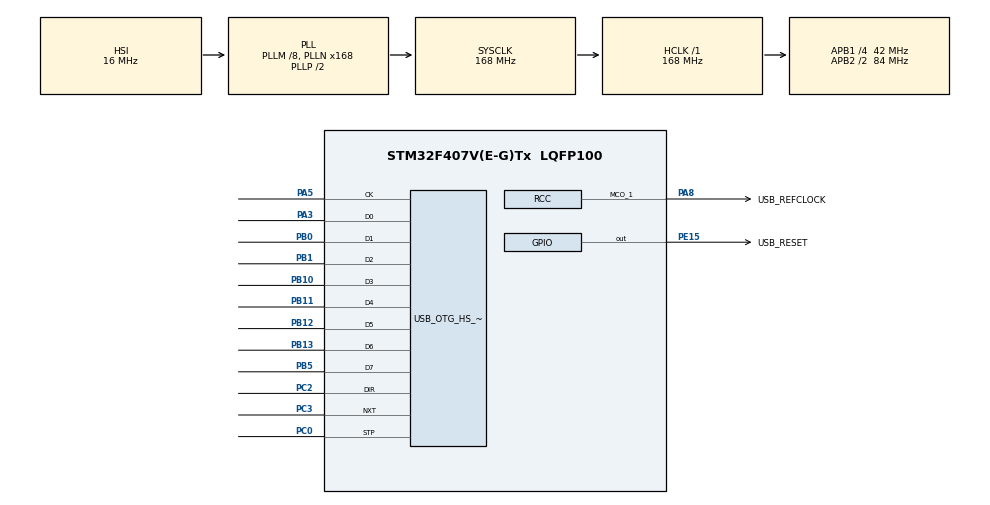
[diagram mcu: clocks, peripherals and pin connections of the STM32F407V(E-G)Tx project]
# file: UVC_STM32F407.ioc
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AL94.I-CUBE-USBD-COMPOSITE.1.0.3.CompositeCcUSBJjCOMPOSITEJjCDCIiACM=true
AL94.I-CUBE-USBD-COMPOSITE.1.0.3.CompositeCcUSBJjCOMPOSITEJjCOMPOSITE=true
AL94.I-CUBE-USBD-COMPOSITE.1.0.3.CompositeCcUSBJjCOMPOSITEJjCore=true
AL94.I-CUBE-USBD-COMPOSITE.1.0.3.CompositeCcUSBJjCOMPOSITEJjUVC=true
AL94.I-CUBE-USBD-COMPOSITE.1.0.3._USBD_USE_CDC_ACM=false
AL94.I-CUBE-USBD-COMPOSITE.1.0.3._USBD_USE_HS=true
AL94.I-CUBE-USBD-COMPOSITE.1.0.3._USBD_USE_UVC=true
Mcu.Family=STM32F4
Mcu.Name=STM32F407V(E-G)Tx
Mcu.Package=LQFP100
NVIC.OTG_HS_IRQn=true\:0\:0\:false\:false\:true\:true\:true\:true
NVIC.PriorityGroup=NVIC_PRIORITYGROUP_4
PA13.Mode=JTAG_5_pins
PA13.Signal=SYS_JTMS-SWDIO
PA14.Mode=JTAG_5_pins
PA14.Signal=SYS_JTCK-SWCLK
PA15.Mode=JTAG_5_pins
PA15.Signal=SYS_JTDI
PA3.Mode=Device_HS
PA3.Signal=USB_OTG_HS_ULPI_D0
PA5.Mode=Device_HS
PA5.Signal=USB_OTG_HS_ULPI_CK
PA8.GPIO_Label=USB_REFCLOCK
PA8.GPIO_Speed=GPIO_SPEED_FREQ_MEDIUM
PA8.Mode=Clock-out-1
PA8.Signal=RCC_MCO_1
PB0.Mode=Device_HS
PB0.Signal=USB_OTG_HS_ULPI_D1
PB1.Mode=Device_HS
PB1.Signal=USB_OTG_HS_ULPI_D2
PB10.Mode=Device_HS
PB10.Signal=USB_OTG_HS_ULPI_D3
PB11.Mode=Device_HS
PB11.Signal=USB_OTG_HS_ULPI_D4
PB12.Mode=Device_HS
PB12.Signal=USB_OTG_HS_ULPI_D5
PB13.Mode=Device_HS
PB13.Signal=USB_OTG_HS_ULPI_D6
PB3.Mode=JTAG_5_pins
PB3.Signal=SYS_JTDO-SWO
PB4.Mode=JTAG_5_pins
PB4.Signal=SYS_JTRST
PB5.Mode=Device_HS
PB5.Signal=USB_OTG_HS_ULPI_D7
PC0.Mode=Device_HS
PC0.Signal=USB_OTG_HS_ULPI_STP
PC2.Mode=Device_HS
PC2.Signal=USB_OTG_HS_ULPI_DIR
PC3.Mode=Device_HS
PC3.Signal=USB_OTG_HS_ULPI_NXT
PE1.Signal=DCMI_D3
PE15.GPIO_Label=USB_RESET
PE15.Signal=GPIO_Output
PH0-OSC_IN.Mode=HSE-External-Oscillator
PH0-OSC_IN.Signal=RCC_OSC_IN
PH1-OSC_OUT.Mode=HSE-External-Oscillator
PH1-OSC_OUT.Signal=RCC_OSC_OUT
ProjectManager.HeapSize=0x200
ProjectManager.StackSize=0x400
ProjectManager.TargetToolchain=STM32CubeIDE
RCC.48MHZClocksFreq_Value=84000000
RCC.AHBFreq_Value=168000000
RCC.APB1CLKDivider=RCC_HCLK_DIV4
RCC.APB1Freq_Value=42000000
RCC.APB1TimFreq_Value=84000000
RCC.APB2CLKDivider=RCC_HCLK_DIV2
RCC.APB2Freq_Value=84000000
RCC.APB2TimFreq_Value=168000000
RCC.CortexFreq_Value=168000000
RCC.HCLKFreq_Value=168000000
RCC.HSE_VALUE=24000000
RCC.HSI_VALUE=16000000
RCC.LSE_VALUE=32768
RCC.PLLM=8
RCC.PLLN=168
RCC.RCC_MCO1Source=RCC_MCO1SOURCE_HSE
RCC.RCC_MCO2Source=RCC_MCO2SOURCE_HSE
RCC.SYSCLKFreq_VALUE=168000000
RCC.SYSCLKSource=RCC_SYSCLKSOURCE_PLLCLK
RCC.VCOOutputFreq_Value=336000000
USB_OTG_HS.VirtualMode-Device_HS=Device_HS
USB_OTG_HS.dma_enable-Device_HS=DISABLE
USB_OTG_HS.low_power_enable-Device_HS=DISABLE
VP_AL94.I-CUBE-USBD-COMPOSITE_VS_USBJjComposite_1.0.0_1.0.3.Mode=USBJjComposite
board=custom

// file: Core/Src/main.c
/* USER CODE BEGIN Header */
/**
  ******************************************************************************
  * @file           : main.c
  * @brief          : Main program body
  ******************************************************************************
  * @attention
  *
  * Copyright (c) 2024 STMicroelectronics.
  * All rights reserved.
  *
  * This software is licensed under terms that can be found in the LICENSE file
  * in the root directory of this software component.
  * If no LICENSE file comes with this software, it is provided AS-IS.
  *
  ******************************************************************************
  */
/* USER CODE END Header */
#include "main.h"
#include "usb_otg.h"
#include "gpio.h"

/* USER CODE BEGIN Includes */
#include "usbd_composite.h"//user modify
#include "usbd_video.h"

/* USER CODE END Includes */

void SystemClock_Config(void);
/* USER CODE BEGIN PFP */
int8_t bTerminalConnect;
uint8_t img_count;

extern USBD_HandleTypeDef hUsbDevice;
extern void MX_USB_DEVICE_Init(void);

#ifdef USBD_UVC_FORMAT_UNCOMPRESSED
#define IMAGE1_SIZE  	UVC_WIDTH*UVC_HEIGHT*2
#define IMAGE2_SIZE		UVC_WIDTH*UVC_HEIGHT*2

#else
#define IMAGE1_SIZE  	4518
#define IMAGE2_SIZE		4474
#endif

#ifdef USBD_UVC_FORMAT_UNCOMPRESSED
const  uint8_t image1[IMAGE1_SIZE] = {
		 0xFF, 0xFF, 0xFF, 0xFF, 0xFF, 0xFF, 0xFF, 0xFF, 0xFF, 0xFF, 0xFF, 0xFF, 0xFF, 0xFF, 0xFF, 0xFF, 0xFF, 0xFF, 0xFF, 0xFF,
		 0xFF, 0xFF, 0xFF, 0xFF, 0xFF, 0xFF, 0xFF, 0xFF, 0xFF, 0xFF, 0xFF, 0xFF, 0xFF, 0xFF, 0xFF, 0xFF, 0xFF, 0xFF, 0xFF, 0xFF,
		 0xFF, 0xFF, 0xFF, 0xFF, 0xFF, 0xFF, 0xFF, 0xFF, 0xFF, 0xFF, 0xFF, 0xFF, 0xFF, 0xFF, 0xFF, 0xFF, 0xFF, 0xFF, 0xFF, 0xFF,
		 0xFF, 0xFF, 0xFF, 0xFF, 0xFF, 0xFF, 0xFF, 0xFF, 0xFF, 0xFF, 0xFF, 0xFF, 0xFF, 0xFF, 0xFF, 0xFF, 0xFF, 0xFF, 0xFF, 0xFF,
		 0xFF, 0xFF, 0xFF, 0xFF, 0xFF, 0xFF, 0xFF, 0xFF, 0xFF, 0xFF, 0xFF, 0xFF, 0xFF, 0xFF, 0xFF, 0xFF, 0xFF, 0xFF, 0xFF, 0xFF,
		 0xFF, 0xFF, 0xFF, 0xFF, 0xFF, 0xFF, 0xFF, 0xFF, 0xFF, 0xFF, 0xFF, 0xFF, 0xFF, 0xFF, 0xFF, 0xFF, 0xFF, 0xFF, 0xFF, 0xFF,
		 0xFF, 0xFF, 0xFF, 0xFF, 0xFF, 0xFF, 0xFF, 0xFF, 0xFF, 0xFF, 0xFF, 0xFF, 0xFF, 0xFF, 0xFF, 0xFF, 0xFF, 0xFF, 0xFF, 0xFF,
		 0xFF, 0xFF, 0xFF, 0xFF, 0xFF, 0xFF, 0xFF, 0xFF, 0xFF, 0xFF, 0xFF, 0xFF, 0xFF, 0xFF, 0xFF, 0xFF, 0xFF, 0xFF, 0xFF, 0xFF,
		 0xFF, 0xFF, 0xFF, 0xFF, 0xFF, 0xFF, 0xFF, 0xFF, 0xFF, 0xFF, 0xFF, 0xFF, 0xFF, 0xFF, 0xFF, 0xFF, 0xFF, 0xFF, 0xFF, 0xFF,
		 0xFF, 0xFF, 0xFF, 0xFF, 0xFF, 0xFF, 0xFF, 0xFF, 0xFF, 0xFF, 0xFF, 0xFF, 0xFF, 0xFF, 0xFF, 0xFF, 0xFF, 0xFF, 0xFF, 0xFF,
		};
const  uint8_t image2[IMAGE1_SIZE]= {
		 0x51, 0x51, 0x51, 0x51, 0x51, 0x51, 0x51, 0x51, 0x51, 0x51, 0x51, 0x51, 0x51, 0x51, 0x51, 0x51, 0x51, 0x51, 0x51, 0x51,
		 0x51, 0x51, 0x51, 0x51, 0x51, 0x51, 0x51, 0x51, 0x51, 0x51, 0x51, 0x51, 0x51, 0x51, 0x51, 0x51, 0x51, 0x51, 0x51, 0x51,
		 0x51, 0x51, 0x51, 0x51, 0x51, 0x51, 0x51, 0x51, 0x51, 0x51, 0x51, 0x51, 0x51, 0x51, 0x51, 0x51, 0x51, 0x51, 0x51, 0x51,
		 0x51, 0x51, 0x51, 0x51, 0x51, 0x51, 0x51, 0x51, 0x51, 0x51, 0x51, 0x51, 0x51, 0x51, 0x51, 0x51, 0x51, 0x51, 0x51, 0x51,
		 0x51, 0x51, 0x51, 0x51, 0x51, 0x51, 0x51, 0x51, 0x51, 0x51, 0x51, 0x51, 0x51, 0x51, 0x51, 0x51, 0x51, 0x51, 0x51, 0x51,
		 0x51, 0x51, 0x51, 0x51, 0x51, 0x51, 0x51, 0x51, 0x51, 0x51, 0x51, 0x51, 0x51, 0x51, 0x51, 0x51, 0x51, 0x51, 0x51, 0x51,
		 0x51, 0x51, 0x51, 0x51, 0x51, 0x51, 0x51, 0x51, 0x51, 0x51, 0x51, 0x51, 0x51, 0x51, 0x51, 0x51, 0x51, 0x51, 0x51, 0x51,
		 0x51, 0x51, 0x51, 0x51, 0x51, 0x51, 0x51, 0x51, 0x51, 0x51, 0x51, 0x51, 0x51, 0x51, 0x51, 0x51, 0x51, 0x51, 0x51, 0x51,
		 0x51, 0x51, 0x51, 0x51, 0x51, 0x51, 0x51, 0x51, 0x51, 0x51, 0x51, 0x51, 0x51, 0x51, 0x51, 0x51, 0x51, 0x51, 0x51, 0x51,
		 0x51, 0x51, 0x51, 0x51, 0x51, 0x51, 0x51, 0x51, 0x51, 0x51, 0x51, 0x51, 0x51, 0x51, 0x51, 0x51, 0x51, 0x51, 0x51, 0x51,
		};

#else

const  uint8_t image1[IMAGE1_SIZE] = {

/* Video Frame 1 */
0xFF,0xD8,0xFF,0xE0,0x00,0x21,0x41,0x56,
0x49,0x31,0x00,0x01,0x01,0x01,0x00,0x78,
0x00,0x78,0x00,0x00,0x00,0x00,0x00,0x00,
0x00,0x00,0x00,0x00,0x00,0x00,0x00,0x00,
0x00,0x00,0x00,0x00,0x00,0xFF,0xDB,0x00,
0x43,0x00,0x04,0x02,0x03,0x03,0x03,0x02,
0x04,0x03,0x03,0x03,0x04,0x04,0x04,0x04,
0x06,0x0A,0x06,0x06,0x05,0x05,0x06,0x0C,
0x08,0x09,0x07,0x0A,0x0E,0x0C,0x0F,0x0F,
0x0E,0x0C,0x0E,0x0F,0x10,0x12,0x17,0x13,
0x10,0x11,0x15,0x11,0x0D,0x0E,0x14,0x1A,
0x14,0x15,0x17,0x18,0x19,0x1A,0x19,0x0F,
0x13,0x1C,0x1E,0x1C,0x19,0x1E,0x17,0x19,
0x19,0x18,0xFF,0xDB,0x00,0x43,0x01,0x04,
0x04,0x04,0x06,0x05,0x06,0x0B,0x06,0x06,
0x0B,0x18,0x10,0x0E,0x10,0x18,0x18,0x18,
0x18,0x18,0x18,0x18,0x18,0x18,0x18,0x18,
0x18,0x18,0x18,0x18,0x18,0x18,0x18,0x18,
0x18,0x18,0x18,0x18,0x18,0x18,0x18,0x18,
0x18,0x18,0x18,0x18,0x18,0x18,0x18,0x18,
0x18,0x18,0x18,0x18,0x18,0x18,0x18,0x18,
0x18,0x18,0x18,0x18,0x18,0x18,0x18,0xFF,
0xC0,0x00,0x11,0x08,0x00,0x90,0x00,0xB0,
0x03,0x01,0x21,0x00,
0x02,0x11,0x01,0x03,0x11,0x01,0xFF,0xDA,
0x00,0x0C,0x03,0x01,0x00,0x02,0x11,0x03,
0x11,0x00,0x3F,0x00,0xE4,0x2D,0x98,0x60,
0x1F,0xE5,0x5A,0x16,0xEC,0x30,0x3D,0x6B,
0xD4,0xB9,0x0D,0x97,0x6D,0x9F,0x9F,0xFE,
0xBD,0x5F,0x81,0xF2,0x00,0xE2,0x82,0x1B,
0x2D,0x40,0xF8,0x03,0xD6,0xAD,0xC6,0xFC,
0x0F,0x4A,0x77,0xBE,0xC4,0xB4,0x58,0x89,
0xBD,0x39,0xA9,0xC1,0xE7,0x82,0x31,0x4E,
0xE2,0xB2,0x1E,0xAD,0x8C,0x1E,0x82,0x9E,
0x8C,0x08,0x04,0x62,0x9D,0xC5,0xA0,0x2B,
0x8D,0xD8,0x38,0xE6,0x94,0xC8,0x0B,0x76,
0xE2,0x86,0xC6,0xF7,0x24,0x0E,0x01,0x0D,
0xC5,0x05,0xB2,0x09,0x07,0x9F,0x4A,0x77,
0x0B,0xF4,0x1A,0x08,0x38,0xE7,0xBD,0x2C,
0x8E,0xAC,0x70,0x1B,0xF2,0xA1,0xB0,0xF3,
0x18,0x59,0x48,0xEA,0x32,0x2A,0x27,0x90,
0x10,0x7A,0x7D,0x28,0xBB,0x07,0x66,0xC8,
0x25,0x94,0x86,0xE0,0xE4,0x54,0x32,0x9E,
0x7E,0xB4,0xF5,0x1A,0x6D,0x6C,0x41,0x23,
0x29,0x15,0x4E,0x72,0x30,0x48,0xE4,0xD3,
0x6C,0xAB,0xD9,0x1C,0x35,0xAB,0x82,0x47,
0x3D,0xAA,0xFD,0xB3,0x63,0x1C,0xF3,0x5C,
0xEA,0x45,0x36,0x9E,0xE5,0xE8,0x5B,0x90,
0x46,0x31,0x57,0x61,0x90,0x6D,0x14,0x36,
0x4C,0x8B,0x90,0xC9,0xC0,0xE7,0x3F,0x4A,
0xB3,0x14,0xBC,0x1C,0x1A,0x2E,0xF7,0x21,
0xA2,0x78,0xA4,0xC7,0x7E,0x7E,0xB4,0x4B,
0x7D,0x04,0x38,0xF3,0x24,0x00,0xFA,0x75,
0xA5,0x29,0xA4,0x16,0xBE,0x88,0x6C,0x5A,
0xAA,0xB9,0xFD,0xDA,0x39,0x53,0xDC,0xF0,
0x29,0x5B,0x53,0x54,0x6D,0xAB,0x93,0x93,
0xEB,0x5E,0x7D,0x7C,0xCE,0x9D,0x37,0x64,
0xEE,0x76,0xD2,0xC1,0x4E,0x6A,0xEC,0x8E,
0xEB,0x56,0x78,0xC6,0x22,0xC1,0x61,0x55,
0x5F,0x59,0xBD,0xCE,0x72,0x98,0xFF,0x00,
0x76,0xB8,0x65,0x9C,0xCB,0xA2,0x3A,0x96,
0x5F,0x15,0xD4,0x60,0xD7,0x6F,0x12,0x43,
0x96,0x52,0x3D,0x31,0x4A,0x3C,0x47,0x73,
0xBB,0xE6,0x45,0x2B,0xF4,0xA9,0x59,0xC4,
0xAF,0xAA,0x1F,0xD4,0x21,0xD0,0xB7,0x0F,
0x88,0x22,0x30,0x86,0x74,0x90,0x01,0xD4,
0xF5,0x14,0xC9,0x7C,0x47,0x18,0x90,0x08,
0xE2,0x66,0x41,0xDF,0x38,0xAE,0xAA,0x59,
0xBC,0x65,0xA4,0xCC,0xAA,0x60,0x34,0xF7,
0x4B,0x16,0x7A,0xCD,0xA5,0xC1,0x00,0x39,
0x56,0xFF,0x00,0x6B,0x8A,0xB7,0xE6,0x02,
0x32,0x0E,0x41,0xF7,0xAF,0x5A,0x96,0x22,
0x35,0x15,0xE2,0xCF,0x3E,0x74,0xA5,0x07,
0xEF,0x11,0x49,0x20,0xCF,0x35,0x0C,0x92,
0x12,0x7D,0xAB,0x5E,0x62,0x13,0x2B,0x4A,
0xDF,0x2E,0x2A,0xA4,0xEF,0xC1,0xE7,0x3E,
0xD4,0xDC,0xBB,0x95,
0x63,0x89,0xB5,0x70,0x0E,0x31,0xC8,0xEF,
0x57,0xA0,0x7C,0x10,0x41,0xAC,0x11,0x6E,
0xC5,0xDB,0x79,0x32,0x39,0xE7,0xBD,0x5B,
0x82,0x4E,0x83,0xB7,0x5A,0x77,0xE8,0x46,
0x8B,0x62,0xDC,0x2E,0x38,0xED,0x56,0x12,
0x41,0x9C,0x67,0x14,0x88,0x7E,0x44,0xC5,
0xD8,0xA9,0xDA,0x71,0x9A,0x88,0xC2,0x98,
0xC9,0x1B,0x8F,0xA9,0xAF,0x13,0x35,0xAF,
0x28,0x25,0x08,0xF5,0x3D,0x3C,0x05,0x24,
0xDF,0x33,0x1D,0x73,0x3B,0x3C,0x0B,0x17,
0x00,0x2F,0x03,0x02,0xA2,0xBA,0xB7,0x78,
0x02,0x17,0x23,0x0E,0x33,0x90,0x6B,0xE7,
0x6F,0xAE,0xA7,0xAF,0x6B,0xAB,0x11,0x45,
0x6F,0x34,0xEC,0xC2,0x24,0x67,0x2B,0xC9,
0xDA,0x33,0x81,0x50,0xB6,0x31,0x43,0x92,
0xD9,0x09,0x22,0x09,0xB9,0x6E,0xFC,0x54,
0x4C,0x0E,0x6A,0xAE,0x2B,0x58,0x46,0x2D,
0xB4,0xA8,0x6C,0x2D,0x44,0xE0,0x83,0xD4,
0xD3,0x4E,0xCC,0x63,0xE0,0x94,0xAB,0x7D,
0xEE,0x9D,0xEB,0x5F,0x48,0xBD,0x62,0xBB,
0x18,0xF3,0xD8,0xD7,0xA3,0x81,0xAF,0x2A,
0x75,0x15,0x8E,0x7C,0x4D,0x28,0xCE,0x0E,
0xE6,0x84,0xCF,0xB8,
0x0C,0x91,0xC5,0x46,0xEC,0xDB,0x7A,0xE2,
0xBE,0xB5,0x3D,0x0F,0x9F,0xB5,0xB7,0x20,
0x99,0xFD,0xFB,0x73,0x55,0x2E,0x1F,0x8E,
0x0F,0x4A,0xAD,0x87,
0xE4,0x71,0x50,0xBF,0xCD,0xFD,0x4D,0x5D,
0xB6,0x72,0x4E,0x0F,0x15,0x82,0xD0,0xB6,
0x5C,0x81,0xF1,0xD6,0xAE,0x45,0x26,0xE5,
0x1D,0x39,0xA6,0xD9,0x16,0x6C,0xB1,0x0C,
0x9C,0x03,0x9E,0x7B,0x55,0x98,0x9D,0x88,
0xCF,0x38,0xA4,0x49,0x66,0x07,0xC9,0x35,
0x33,0xFD,0xDA,0xF9,0xCC,0xE3,0xE3,0x47,
0xAF,0x97,0xAB,0x45,0x90,0x39,0x39,0x15,
0x36,0x9B,0x6F,0x25,0xFD,0xF2,0x5B,0x79,
0x9B,0x43,0x74,0x63,0xD0,0x57,0x8A,0xDD,
0x95,0xCF,0x4D,0x79,0x88,0xD2,0x4F,0xA6,
0xDE,0x4D,0x04,0x52,0x72,0x09,0x42,0x47,
0x7C,0x55,0x16,0x6C,0x03,0x9E,0x73,0x53,
0x17,0x75,0x74,0x29,0x5D,0x68,0x66,0xEA,
0x17,0xB6,0x96,0x87,0x37,0x57,0x11,0x45,
0x9F,0xEF,0x1C,0x56,0x64,0x1E,0x38,0xB5,
0xD3,0x2F,0xDD,0xE2,0xB4,0x8A,0xF1,0x4A,
0x95,0xC1,0x91,0x71,0x5D,0x10,0xA2,0xE7,
0xA6,0xC6,0x72,0xAB,0x18,0x6E,0x61,0xDD,
0xF8,0xFE,0x08,0x49,0x7B,0x8D,0x3A,0x58,
0xD0,0x93,0x8D,0x8C,0x1B,0x14,0xEB,0x5F,
0x88,0x3A,0x0C,0xA4,0x07,0x99,0xE2,0x27,
0xFB,0xEB,0x5D,0x2B,
0x07,0x2B,0x5E,0x2E,0xE6,0x0F,0x19,0x14,
0xED,0x25,0x63,0xA1,0xD2,0x6F,0xED,0x35,
0x08,0x3C,0xEB,0x39,0xD2,0x64,0x3D,0xD4,
0xE6,0xB5,0xF4,0xD3,0x89,0x57,0x18,0x14,
0x51,0x8B,0x55,0x12,0x66,0xB3,0x92,0x94,
0x1B,0x5B,0x1A,0x85,0xB2,0xBD,0x69,0x8F,
0x21,0x0B,0xCE,0x6B,0xEC,0x63,0x2D,0x2C,
0x7C,0xEB,0x7A,0xB2,0xBB,0xB9,0x27,0x8C,
0xD5,0x59,0xC9,0xE7,0x35,0x77,0x1D,0xED,
0xB9,0xC6,0x5B,0xB1,0xAB,0x96,0xEC,0x7A,
0x74,0xF7,0xAC,0x2E,0x68,0xDE,0xB6,0x2F,
0x42,0x72,0x2A,0xD4,0x1F,0x74,0x03,0x9A,
0x77,0xEE,0x26,0xCD,0x1B,0x0B,0x5B,0x9B,
0x86,0x09,0x04,0x32,0x48,0xC7,0xB2,0xAE,
0x6B,0x62,0x3F,0x0D,0x6B,0xA6,0x30,0xC7,
0x4D,0xB8,0x00,0xFF,0x00,0xB3,0x59,0x4E,
0xAC,0x63,0xBB,0x14,0x69,0x4E,0x5A,0xC5,
0x0D,0x3A,0x75,0xF5,0xA1,0x26,0xE6,0xD6,
0x58,0x80,0xEE,0xCB,0x8A,0x08,0xE3,0xD6,
0xBE,0x77,0x37,0x9A,0x94,0xD3,0x47,0xAD,
0x81,0x8B,0x8C,0x5A,0x91,0x14,0x88,0x49,
0xC8,0xC5,0x36,0xDE,0x47,0x82,0x4F,0x32,
0x36,0xDA,0xC0,0x62,
0xBC,0x8B,0xF4,0x3B,0xAE,0x3D,0x63,0x69,
0x2E,0x23,0x92,0xE1,0xB1,0x1C,0x8E,0x37,
0x37,0x7C,0x66,0xB3,0x3C,0x7D,0x7F,0xA7,
0xE8,0xC5,0xCC,0x17,0x0C,0x55,0xD7,0xE4,
0x2C,0x32,0x41,0xFC,0x28,0x84,0x5C,0xA4,
0x92,0x41,0x26,0x92,0xBB,0x3C,0x9F,0x5B,
0xD4,0x65,0xD4,0x6E,0x0B,0xDC,0xDE,0x5B,
0xC8,0x01,0xE3,0x74,0x47,0x8A,0xC2,0xD5,
0x27,0x86,0x08,0xCA,0xA7,0xD8,0xA4,0x63,
0xC1,0xC0,0x2A,0x45,0x7B,0x54,0xE1,0x64,
0xA2,0x93,0x3C,0xBA,0x93,0x52,0xF7,0x9B,
0x31,0x7C,0x8B,0xAB,0x82,0x42,0xA9,0x71,
0xE8,0xB2,0x67,0x15,0x2D,0xA6,0x85,0xAA,
0xDC,0x16,0xF2,0x6C,0xEE,0x18,0x2F,0x53,
0x8C,0xD7,0x57,0x3C,0x63,0xB9,0xCB,0xCB,
0x26,0xF4,0x2E,0x78,0x73,0x53,0xD4,0xFC,
0x35,0xAC,0x21,0x93,0x72,0x2E,0x40,0x74,
0x75,0x20,0x11,0x5E,0xEF,0xE1,0xEB,0x98,
0xEF,0x2D,0x21,0xBA,0x8D,0x81,0x59,0x14,
0x11,0x8A,0xC6,0xAC,0x53,0x9C,0x6A,0x23,
0xAA,0x84,0xDA,0x52,0x83,0x35,0x24,0x72,
0xCB,0xF3,0x64,0x0C,0xE2,0xA2,0x67,0xE4,
0x6D,0xC9,0xC7,0x5E,
0x6B,0xE8,0xE2,0x95,0x8F,0x2D,0xBD,0x75,
0x21,0x94,0x9C,0x03,0xD7,0x3E,0xF5,0x5E,
0x56,0x62,0x7D,0xCD,
0x52,0x1A,0x38,0xC8,0x09,0x18,0xC7,0x15,
0x72,0x13,0xD0,0xD6,0x17,0x35,0x92,0x56,
0x2F,0xDB,0x92,0x48,0x1F,0xD2,0xBA,0xAF,
0x0D,0x68,0xF0,0x88,0x96,0xEA,0xFF,0x00,
0xEE,0x9E,0x44,0x63,0xBD,0x73,0xE2,0xF1,
0x0A,0x8C,0x1C,0xBA,0x97,0x42,0x97,0xB5,
0x9D,0x8E,0xB3,0x4C,0xBC,0xB9,0x85,0x97,
0xFB,0x3E,0x04,0x85,0x57,0xA1,0xC5,0x5B,
0xBA,0xD7,0xF5,0xA8,0xC7,0xCD,0xA8,0xA8,
0x3E,0x9C,0x57,0xCC,0xCE,0x73,0xAB,0x2B,
0xEE,0xCF,0x71,0x46,0x34,0xD5,0x96,0x86,
0x75,0xEE,0xAF,0xA8,0xDF,0xC2,0xD1,0x5D,
0x48,0x1C,0x0E,0xE0,0x56,0x43,0x0E,0xBC,
0x9C,0xD7,0x34,0xDB,0xD9,0x94,0x95,0xF6,
0x21,0x71,0xCE,0x39,0x35,0x19,0x4E,0x38,
0xAC,0x98,0xEE,0x24,0xD2,0x66,0x20,0xA4,
0xF0,0xB5,0xE7,0xDF,0x14,0x2F,0x6D,0xA7,
0xBE,0x8D,0x2D,0x5E,0xE7,0xE4,0x18,0x70,
0x84,0x10,0x6B,0x7C,0x3C,0x5B,0x99,0x95,
0x67,0xEE,0xB3,0x8D,0x9E,0x4D,0x91,0x96,
0x2F,0x76,0x00,0x19,0xC9,0x50,0x71,0x4D,
0xF0,0xFE,0x9B,0xA2,0x6A,0x73,0x35,0xD5,
0xFE,0xA1,0x8D,0xAD,0xF7,0x5D,0x70,0x4D,
0x7A,0xA9,0xB8,0xAB,0xC5,0x6A,0x79,0xAD,
0x29,0x35,0x19,0x33,0xD0,0xFC,0x3B,0xA2,
0xF8,0x7E,0x28,0x8C,0x9A,0x7C,0x30,0xB6,
0x47,0x24,0x0A,0xD7,0x8A,0xDA,0x08,0x89,
0x11,0xC4,0x8A,0x0F,0x5C,0x0A,0xF3,0x2A,
0xCE,0x72,0x97,0xBC,0x7A,0x34,0xE3,0x15,
0x1F,0x74,0xAB,0xAA,0xE9,0x16,0x37,0xD6,
0xD2,0x47,0x35,0xBC,0x64,0xB8,0xC0,0x25,
0x79,0x14,0xDF,0x09,0x5A,0x5C,0xE8,0xF0,
0x25,0x9B,0x95,0x92,0x15,0x27,0x6B,0x81,
0x82,0x3D,0xAB,0xAB,0x0D,0x37,0xCD,0xCA,
0xFA,0x93,0x5A,0x0A,0xDC,0xC8,0xDD,0x2E,
0x41,0x3D,0x08,0x3F,0xCE,0xA0,0x90,0xF2,
0x49,0xC0,0x27,0xDA                    ,
0xBE,0xBA,0x0A,0xC8,0xF0,0x1A,0x22,0x72,
0x73,0xCD,0x43,0x70,0xF8,0x1D,0x30,0x6A,
0xAF,0x71,0x23,0x8E,0x81,0xB9,0xF4,0xE2,
0xAE,0x40,0xC3,0xA7,0x15,0xCE,0x99,0xAB,
0xB5,0xCE,0x87,0xC2,0x96,0xC2,0x7B,0x8F,
0x35,0xC6,0x52,0x3E,0x7F,0x1A,0xEC,0x6C,
0x94,0x39,0xDF,0x21,0xC2,0x25,0x78,0x39,
0x9D,0x4E,0x6A,0x8A,0x9A,0x3D,0x4C,0x04,
0x2D,0x17,0x26,0x50,0xD6,0xBC,0x44,0xC1,
0x8D,0xBD,0x91,0x0A,0x83,0x82,0xC3,0xBD,
0x63,0x1B,0xB9,0xA4,0x7D,0xCF,0x2B,0x13,
0x9C,0xE7,0x26,0xBD,0x0C,0x1E,0x16,0x34,
0xE1,0x76,0xB5,0x67,0x1E,0x2F,0x10,0xE7,
0x2B,0x74,0x46,0xD7,0x87,0xAE,0x9E,0x4C,
0xC4,0xD8,0x38,0x1C,0x1A,0xB8,0x57,0x2C,
0x47,0xA7,0xB5,0x78,0x99,0x9D,0x35,0x0A,
0xAE,0xC7,0xA1,0x82,0x9B,0x9D,0x3D,0x7A,
0x10,0xC8,0x3E,0x6F,0x5F,0xC2,0x98,0x47,
0x1D,0x38,0xFA,0x57,0x9B,0xE4,0x75,0xE8,
0x43,0x78,0x3F,0xD1,0x9F,0x18,0xCE,0xD3,
0xED,0x5E,0x3B,0xAD,0x46,0x1F,0x54,0x9B,
0x72,0x42,0x7E,0x73,0xD6,0x42,0x2B,0xAF,
0x08,0xED,0x26,0x73,0x62,0x7E,0x13,0x2B,
0x59,0x85,0x12,0xD5,0xF6,0x22,0x1E,0x3F,
0x86,0x5E,0x6B,0x95,0x65,0x70,0x7E,0x5D,
0xE0,0x7B,0x35,0x7B,0x14,0xDF,0x73,0xCB,
0xAA,0xB6,0x36,0xBC,0x3F,0xE2,0x5D,0x57,
0x48,0x50,0x90,0x3C,0x85,0x3B,0x83,0xCD,
0x6F,0xBF,0xC4,0xAD,0x44,0x94,0x1E,0x46,
0xDC,0x7D,0xEF,0x97,0xAD,0x67,0x53,0x0B,
0x19,0xBE,0x63,0x4A,0x58,0x89,0xD3,0x56,
0x3B,0x0F,0x03,0xF8,0x99,0x35,0x88,0xCE,
0xF6,0xC3,0x13,0xC7,0x18,0xC5,0x6F,0x3D,
0xFD,0xBF,0x9C,0x90,0xC7,0x22,0xB3,0xB1,
0xE8,0xA7,0x35,0xCB,0x0A,0x2E,0x35,0x94,
0x51,0xDA,0xAB,0x73                    ,
0xD3,0x6D,0x96,0xDA,0x45,0xC6,0x5B,0x3C,
0x54,0x32,0x38,0x27,0x77,0x6A,0xFA,0xA8,
0xBB,0x1E,0x1B,0xB9,0x13,0xBF,0xCD,0x8A,
0xAF,0x3B,0xFC,0xC7,0xDF,0xA5,0x53,0x63,
0xBE,0x88,0xE3,0xED,0xDB,0x20,0x73,0xC1,
0xAB,0xB6,0xCD,0x92,0x00,0xCF,0x35,0x82,
0x35,0xB1,0xDC,0xF8,0x72,0x0F,0x23,0x4E,
0x8C,0x63,0x05,0xB9,0x35,0x63,0xC4,0x77,
0xE6,0xDA,0xC4,0x5B,0xC6,0x40,0x67,0x1C,
0xF3,0x5F,0x37,0x2F,0xDE,0xE2,0xB5,0xEE,
0x7B,0x11,0x7E,0xCF,0x0F,0x7F,0x23,0x9B,
0x46,0x25,0xB9,0x27,0x93,0x52,0x23,0x60,
0x7B,0xD7,0xD2,0xAD,0x16,0x87,0x82,0xDD,
0xF5,0x36,0xFC,0x2A,0xD9,0xBA,0x3C,0xF6,
0xAD,0x97,0xEA,0x40,0xAF,0x99,0xCD,0xDF,
0xEF,0xAC,0x7B,0x59,0x73,0xFD,0xD9,0x1B,
0x0F,0x9B,0xA5,0x31,0xC7,0x1D,0x2B,0xC9,
0xB5,0xB5,0x3B,0x48,0xE6,0x5D,0xD1,0x15,
0x23,0x86,0x18,0xAF,0x27,0xF1,0x7D,0xAF,
0xD9,0x35,0x99,0x51,0x8A,0x80,0xC7,0x23,
0xE4,0xCD,0x75,0x61,0x64,0xF9,0xAC,0x8E,
0x7C,0x42,0x4E,0x37,0x30,0x75,0x14,0x47,
0xB6,0x75,0xDC,0x9C,0x8F,0xF9,0xE7,0x5C,
0x6D,0xCE,0x12,0x46,0x53,0xB4,0x10,0x6B,
0xD9,0xA2,0xEE,0xF5,0x3C,0xBA,0xCA,0xE8,
0x8D,0x5C,0x63,0xB6,0x7D,0x8D,0x27,0x98,
0x72,0x39,0x61,0xF4                    ,
0x6A,0xDD,0x23,0x03,0xBE,0xF8,0x3F,0x74,
0xB0,0xC7,0x79,0x34,0xDB,0xFC,0xB8,0x53,
0x76,0x49,0xC8,0xAE,0xA3,0xE1,0xCB,0xDB,
0xEA,0x3F,0x69,0xD4,0x70,0xC3,0xF7,0x98,
0x42,0x6B,0x9D,0x45,0xAA,0xAE,0x4B,0xC8,
0xEE,0x83,0x5E,0xCD,0x26,0x75,0x52,0x3E,
0x0E,0x7B,0x54,0x72,0xBF,0x18,0xC9,0xAF,
0x71,0x3D,0x0F,0x3A,0xC4,0x32,0x30,0xEA,
0x47,0x4F,0x4A,0x82,0x46,0xC8,0xEF,0x56,
0x98,0x75,0x39,0x2B,0x76,0xF9,0x40,0xFC,
0xAB,0x47,0x4C,0xC3,0x5C,0xC4,0x83,0xBB,
0x01,0x5C,0xD2,0x7A,0x33,0x7E,0xA7,0x7F,
0x03,0xAA,0x22,0xA8,0x07,0xE5,0x02,0xB0,
0x7C,0x43,0x71,0xE6,0xDF,0x9C,0x9E,0x17,
0xA5,0x78,0x58,0x1F,0x7A,0xBB,0x93,0x3D,
0x3C,0x5F,0xBB,0x44,0xAB,0x13,0xF1,0xEE,
0x6A,0x50,0x72,0x41,0xF4,0xAF,0xA1,0x47,
0x88,0xF5,0x36,0xBC,0x20,0x4F,0xDA,0x98,
0x1E,0x00,0x15,0xD0,0x37,0x53,0xD2,0xBE,
0x67,0x37,0x7F,0xBE,0x3D,0xAC,0x02,0xFD,
0xD8,0xC6,0xEB,0x4C,0x93,0x80,0x7E,0xB5,
0xE4,0xDC,0xED,0x64,0x64,0x01,0xEF,0x5C,
0xD7,0x8F,0x74,0x6F,0xB7,0x5A,0x9B,0x88,
0x8B,0x07,0x8C,0x67,0x0B,0xD4,0xD6,0x94,
0xE5,0xCB,0x24,0xC8,0x9A,0xE6,0x4D,0x1E,
0x6F,0x72,0xB2,0xC4,0xE5,0x5E,0x39,0xD4,
0x8E,0x30,0x6B,0x99,0xF1,0x25,0x83,0x87,
0x33,0xC5,0x14,0x9B,0x4F,0x2C,0x48,0xAF,
0x6A,0x93,0x4A,0x57,0x47,0x97,0x52,0x37,
0x56,0x31,0x31,0xC1,0xED,0xDB,0xA5,0x2D,
0xBC,0x26,0x69,0xD2,0x24,0x03,0x73,0x9C,
0x74,0xAE,0xC4,0xCE                    ,
0x3B,0x68,0x77,0x5E,0x20,0xB7,0x5F,0x0D,
0xF8,0x66,0x1D,0x36,0xD8,0x01,0x73,0x7C,
0xB9,0x90,0xE3,0xB5,0x76,0xDF,0x0D,0xF4,
0xB6,0xB0,0xF0,0xBD,0xBC,0x6E,0xA4,0x3C,
0x9F,0x39,0xE6,0xB9,0x15,0x4D,0x79,0xBB,
0xB3,0xBE,0x30,0x6A,0xD1,0x5D,0x11,0xB1,
0x23,0xFC,0xA7,0x20,0x73,0x50,0xB3,0x12,
0x99,0x3C,0x11,0x5E,0xFA,0xD5,0x1E,0x73,
0xDC,0x85,0xDF,0xE6,0xFA,0xD4,0x52,0xBE,
0x14,0xF3,0xCD,0x50                    ,
0x5D,0xF5,0x39,0x3B,0x53,0x85,0xE7,0x15,
0xAF,0xE1,0xDF,0x9B,0x54,0x80,0x71,0xF7,
0xAB,0x9E,0x7F,0x0B,0x37,0xB2,0xE6,0xD4,
0xED,0xA7,0x72,0xAE,0x47,0x19,0xAE,0x6B,
0x52,0x7C,0xDF,0x49,0xCE,0x40,0x35,0xE2,
0xE5,0x6B,0xF7,0x8D,0x9E,0x86,0x3D,0xBF,
0x66,0x84,0x89,0x86,0xE1,0x53,0xC6,0x79,
0x39,0x39,0xAF,0x7C,0xF1,0x8D,0xDF,0x07,
0x9C,0xDD,0x30,0xF4,0x15,0xD1,0x1E,0x18,
0xFB,0xD7,0xCB,0xE6,0xEF,0xF7,0xC7,0xB5,
0x97,0xBB,0xD3,0x18,0xD8,0xDD,0xDA,0x98,
0xF8,0xC5,0x79,0x09,0xA3,0xB6,0xC3,0x18,
0x0F,0xC7,0xE9,0x4C,0x71,0x91,0x8F,0x5F,
0x6A,0xAE,0x82,0x5D,0x8E,0x7B,0x5E,0xF0,
0xBD,0x96,0xA5,0x29,0x99,0xC3,0x2B,0xE3,
0xF8,0x4E,0x2B,0x8D,0xD6,0xFC,0x25,0x79,
0x11,0x65,0x8A,0xD1,0xA6,0x8C,0xF6,0xDD,
0x5D,0xD4,0x2B,0xDB,0xDD,0x91,0xCF,0x52,
0x8D,0xF5,0x47,0x2D,0xAA,0x78,0x33,0x57,
0x79,0xB7,0x5B,0x69,0xEF,0x1A,0xFA,0x66,
0xAD,0xF8,0x27,0xC1,0x7A,0x9A,0xEB,0xF0,
0xC9,0x7D,0x03,0x24,0x51,0x9D,0xC4,0x9A,
0xF4,0x3E,0xB1,0x05,0x1D,0xF5,0x38,0x9E,
0x1E,0x77,0xBA,0x5A,0x1D,0x85,0xE7,0x85,
0x67,0xD5,0x7C,0x4C,0xB7,0xF7,0xCE,0x16,
0xDE,0x02,0x02,0x45                    ,
0x8E,0xB5,0xD2,0x5F,0xE2,0x0B,0x64,0x54,
0xF9,0x02,0xF0,0x00,0x15,0xCB,0x46,0xA2,
0x94,0xE3,0x14,0x76,0x3A,0x69,0x27,0x26,
0x67,0x33,0xFC,0xB4,0xD2,0xE3,0x07,0xD2,
0xBE,0xA6,0xF6,0x3C,0x34,0x42,0xF2,0xF1,
0xC1,0xA8,0xA7,0x7C,0xAE,0x4E,0x39,0xA7,
0xEA,0x52,0xEE,0x73,0x36,0xFD,0x3D,0xAB,
0x57,0xC3,0xCC,0x17,0x57,0x80,0xF6,0xDD,
0x8A,0xE7,0x9E,0xB1,0x66,0xA9,0xEA,0x8E,
0xDB,0x50,0x1B,0x65,0xEE,0x33,0x5C,0xC6,
0xAC,0x0A,0x5F,0xBF,0xB9,0xAF,0x23,0x2C,
0x97,0xEF,0x19,0xE9,0x63,0xEC,0xE9,0xA1,
0x20,0x23,0xDF,0x23,0xDA,0xA7,0x42,0x0F,
0x7A,0xF7,0x7C,0xCF,0x15,0x9B,0xFE,0x09,
0xE6,0xE5,0xBE,0x95,0xD3,0x11,0xF3,0x1C,
0x93,0x8A,0xF9,0x7C,0xDB,0x5A,0xC7,0xB5,
0x97,0xFF,0x00,0x0C,0x6C,0x89,0x91,0x9C,
0xD4,0x6C,0xBC,0xF3,0xDE,0xBC,0xA4,0xBA,
0x1D,0xC3,0x0A,0xE7,0x39,0xA6,0x15,0xE3,
0xE9,0x57,0x6D,0x04,0x31,0x87,0xAD,0x46,
0xEB,0xC1,0xC0,0xA6,0xB4,0xD4,0x48,0x85,
0xD3,0x9F,0x4A,0x6B,0x46,0x73,0xD3,0x22,
0xA9,0x2D,0x41,0x20,0x29,0x83,0xCD,0x55,
0xD6,0x06,0x2C,0xD8,0xF1,0x8F,0x5A,0xE9,
0xC3,0x7F,0x11,0x11,0x55,0x7B,0x8C,0xC3,
0x91,0xC6,0x32,0x0E,0x31,0x50,0xCE,0xFF,
0x00,0x2E,0x79,0xAF,0xAE,0xE8,0x7C,0xFA,
0x21,0xF3,0x30,0x3A,0xFE,0x74,0xC9,0x1B,
0x3E,0xF4,0xEF,0xD1                    ,
0x02,0x32,0x21,0xB1,0xB9,0x5F,0xBD,0x17,
0xEB,0x57,0x6C,0xAD,0xAE,0x62,0x9D,0x24,
0x11,0x7D,0xD6,0x07,0xA8,0xAE,0x57,0x38,
0xB5,0xB9,0xD3,0xEC,0xDD,0xF5,0x3B,0xDD,
0x46,0x32,0xF6,0x91,0x5C,0x01,0xF7,0x94,
0x73,0x5C,0xF6,0xB9,0x67,0x2C,0xAE,0xB2,
0xC3,0x1B,0x36,0x46,0x08,0x03,0x35,0xE3,
0xE0,0xA5,0xC9,0x5D,0xA6,0x7A,0x58,0x95,
0xCD,0x48,0xA3,0x1D,0x9D,0xEF,0x39,0xB6,
0x94,0xE3,0xFD,0x9A,0x9E,0x2B,0x5B,0xC0,
0x46,0x6D,0xE4,0xFF,0x00,0xBE,0x4D,0x7B,
0xDC,0xCB,0xB9,0xE3,0x38,0x3E,0xC7,0x49,
0xE0,0x6B,0x79,0x56,0x79,0x0B,0xC6,0xC8,
0x00,0xC7,0x23,0x15,0xD2,0x85,0xC9,0x35,
0xF3,0x39,0xA5,0x9D,0x5B,0x9E,0xBE,0x06,
0x36,0xA6,0x29,0x4E,0x00,0x23,0x8A,0x63,
0xC7,0xC1,0xC0,0xCD,0x79,0x7A,0x9D,0xBB,
0x11,0x14,0xC1,0x39,0x15,0x1B,0x2F,0x35,
0x6C,0x56,0xD4,0x8C,0x8C,0x93,0x8C,0x7E,
0x74,0xC7,0x1C,0xFE,0x34,0x84,0x99,0x11,
0x8F,0xE6,0xE8,0x29,0x64,0x05,0x54,0x01,
0x5A,0x5F,0xA3,0x1D,0x99,0x0B,0x82,0x4E,
0x7B,0xD4,0x7A,0xF4                    ,
0x2C,0x74,0x56,0xF2,0xD4,0xB3,0x9C,0x60,
0x0A,0xDE,0x8C,0xAD,0x24,0x45,0x44,0xDC,
0x1A,0x39,0x64,0xB1,0xD4,0xA4,0x18,0x5B,
0x49,0x4F,0xA6,0x16,0xA6,0x8F,0x46,0xD6,
0x24,0xFB,0xB6,0x72,0x0F,0xA8,0xC5,0x7D,
0x43,0xC4,0xD3,0x4B,0x56,0x78,0x91,0xC3,
0xCD,0xEC,0x8B,0x11,0xF8,0x5F,0x59,0x90,
0x8F,0xDC,0x01,0xF5,0xA9,0x97,0xC1,0xBA,
0x81,0x39,0x92,0x68,0xD7,0xEA,0x6B,0x9A,
0x79,0x95,0x28,0xF5,0x3A,0xA1,0x80,0xA9,
0x25,0xA9,0xDF,0xC3,0xE0,0x0B,0x16,0x51,
0xB9,0xDC,0xFE,0x03,0xFC,0x2A,0xCC,0x5F,
0x0E,0xF4,0xF2,0x00,0xCB,0xE3,0xE8,0x3F,
0xC2,0xB8,0x3D,0xA3,0x3D,0x17,0x4A,0x24,
0xFA,0xD7,0x84,0x05,0xBE,0x8B,0xB2,0x15,
0x67,0x11,0xFA,0xD7,0x17,0x1D,0xB9,0xB6,
0xB8,0x68,0x9B,0x80,0x4E,0x39,0x15,0xC3,
0x29,0xB8,0xD4,0xE6,0x1B,0x82,0x70,0xB2,
0x3D,0x0B,0xC1,0x96,0x5A,0x2C,0xDA,0x6A,
0x23,0x34,0x4D,0x20,0x1C,0xEE,0x18,0xAD,
0x7B,0xED,0x33,0x42,0xB5,0x80,0xCA,0xE9,
0x01,0xC0,0xE8,0x3B,0xD7,0x67,0xB5,0x7B,
0xDC,0xE7,0xF6,0x68,0xE4,0x2E,0x85,0xB4,
0xD7,0x12,0xC9,0x04,0x4A,0xA0,0x74,0x03,
0xD2,0xA1,0xB7,0x84,0xED,0xC9,0x07,0x35,
0xE5,0x57,0xA9,0xCF,0x2B,0xB3,0xAA,0x9C,
0x39,0x50,0x92,0x2F,0x3D,0x2A,0x22,0xBC,
0xE3,0x9A,0xC5,0x15,0x61,0xAC,0xBC,0xE3,
0x19,0xA8,0x27,0x5C,0x1A,0x69,0x8A,0xC4,
0x2C,0x87,0x93,0xCD                    ,
0x23,0x20,0xDB,0x91,0xDF,0xA5,0x35,0xDC,
0x2C,0x30,0x0E,0x0F,0x5A,0x64,0xCA,0x76,
0xE6,0xA9,0x21,0xA4,0x3E,0xD6,0x20,0xD8,
0xC8,0x3C,0xD4,0xFA,0x2E,0x9F,0x75,0x79,
0xE2,0x8F,0x22,0x30,0xE6,0x25,0x8F,0x3C,
0x8E,0x33,0x5B,0xC1,0x6A,0x4B,0xD8,0x74,
0x0D,0xA9,0xAE,0xA1,0x2C,0x57,0x36,0xE6,
0xDE,0x28,0xCE,0x03,0x6C,0xCE,0xEA,0x4B,
0xD5,0xBA,0x33,0x1F,0x2A,0xF8,0x85,0xFA,
0x62,0xA5,0xAB,0x6E,0x5A,0xBF,0x41,0x22,
0xB2,0xBA,0x90,0x7C,0xDA,0x83,0x1C,0xFF,
0x00,0xB5,0x8F,0xE9,0x48,0xDA,0x6C,0xFB,
0xBF,0xE3,0xE5,0x88,0x3E,0xAE,0x7F,0xC2,
0xB3,0x72,0x4B,0x63                    ,
0x55,0x17,0xB9,0xEC,0x36,0xD6,0x90,0x05,
0x03,0x02,0xAD,0xC3,0x04,0x40,0x70,0x05,
0x7A,0x3A,0xBD,0x4C,0x59,0x3F,0xD9,0xE2,
0x78,0xCA,0x32,0x65,0x58,0x73,0x9A,0xE3,
0x7C,0x63,0xE0,0x9F,0x38,0xBD,0xC5,0x82,
0x86,0xC9,0xC9,0x5E,0x86,0xB2,0xAB,0x0E,
0x64,0x25,0x63,0x8E,0x3A,0x65,0xF5,0x83,
0x14,0x78,0x26,0x0D,0xEA,0x01,0xA2,0x38,
0xB5,0x09,0x81,0x55,0x86,0xE6,0x4F,0xA8,
0x35,0xC9,0xFB,0xCB,0x72,0xA1,0xB4,0x96,
0xA5,0xDB,0x1D,0x3E,0xF2,0x16,0x06,0xEA,
0xD9,0xE3,0x0C,0x38,0x2C,0x3A,0xD3,0xE7,
0x45,0x43,0x81,0x81,0x58,0xCA,0x0E,0x1A,
0x32,0xD3,0xBA,0x2A,0x4B,0xD7,0xBD,0x44,
0xDD,0x29,0x74,0x15                    ,
0x86,0x1A,0x89,0xC0,0x24,0xE4,0xD3,0x42,
0x68,0x8E,0x40,0x31,0x50,0x30,0x20,0x91,
0xDA,0xAB,0x98,0x49,0x68,0x21,0xE9,0x48,
0x46,0x4F,0x3D,0xA9,0xAD,0x40,0x9A,0xC9,
0x31,0x29,0x3C,0x62,0xBD,0x13,0xE1,0x2D,
0xAC,0x52,0x6A,0x61,0x99,0x01,0x3B,0x7B,
0xD6,0xB0,0xDE,0xC8,0x34,0x3D,0x06,0xE3,
0x47,0xB1,0x94,0x1F,0x32,0xDA,0x26,0xCF,
0xFB,0x22,0xA8,0x5C,0xF8,0x3F,0x42,0x98,
0xFC,0xF6,0x11,0x0C,0xFA,0x0C,0x56,0xCE,
0x1A,0x84,0x59,0x4E,0x4F,0x87,0xFA,0x01,
0x39,0x10,0x32,0xFD,0x0D,0x47,0xFF,0x00,
0x08,0x06,0x8E,0x00,0x2B,0x1B,0x71,0xFE,
0xD1,0xA3,0x91,0x96                    ,
0xA4,0x55,0x8E,0xFE,0xDD,0x00,0x25,0xFA,
0x53,0xFF,0x00,0xB6,0xAC,0xE3,0x1C,0xB8,
0xE2,0xB5,0x6C,0x52,0x43,0x0F,0x8A,0x34,
0xA8,0x89,0xDF,0x38,0x1F,0x8D,0x46,0x7C,
0x73,0xA0,0xA1,0xC1,0xBB,0x40,0x68,0xB3,
0x7B,0x19,0xCA,0xCB,0x72,0x19,0xBC,0x73,
0xE1,0xB7,0x6C,0x34,0xF0,0xB9,0xF7,0x02,
0x88,0x3C,0x6B,0xE1,0xE0,0x41,0x8E,0x5B,
0x71,0xF4,0x02,0x85,0x06,0xFA,0x19,0xB9,
0xC7,0xB9,0x97,0xE2,0xEF,0x13,0x59,0x6A,
0x0A,0x89,0x6B,0x22,0x48,0x47,0x1F,0x2D,
0x73,0xF3,0xBE,0x4E,0x4D,0x70,0xE2,0x6E,
0xA7,0x63,0x7A,0x6E,0xE8,0xA7,0x33,0x03,
0xD0,0xF3,0x51,0xE4,0x74,0xCD,0x60,0x53,
0x43,0x49,0xE7,0x3D,0xAA,0x27,0x61,0xBB,
0xA8,0xA6,0x85,0x72,0x26,0x3C,0x76,0xF6,
0xA8,0x98,0xF3,0xEF,0x4C,0x43,0x09,0x19,
0x23,0x23,0x3D,0x68,0x04,0x72,0x32,0x31,
0x56,0x86,0xCB,0x36,0xA4,0x06,0x18,0x35,
0xE8,0x1F,0x0A,0x2E,0xA3,0x8B,0x52,0xDC,
0xE4,0xE3,0x6D,0x6D,0x4D,0x6A,0x26,0xB4,
0x3D,0x18,0x6A,0x10,0x31,0xE0,0xD3,0x85,
0xE4,0x5D,0x98,0x57                    ,
0x6A,0x8E,0x86,0x68,0x5F,0xB5,0x44,0x4F,
0x0E,0x29,0x0D,0xC0,0x23,0x86,0x14,0xAD,
0xD8,0xA4,0x71,0x82,0xCA,0x06,0xE0,0xAF,
0x34,0xD9,0x34,0xAB,0x46,0x07,0x29,0xF9,
0x56,0x2D,0xB3,0x69,0x22,0xB4,0xFE,0x1B,
0xD3,0xA5,0x27,0x74,0x7F,0xAD,0x50,0xB8,
0xF0,0x4E,0x91,0x21,0xC9,0x87,0x06,0x8F,
0x68,0xD6,0xE6,0x6E,0x29,0xEE,0x53,0x9F,
0xE1,0xFE,0x90,0xC3,0xE5,0x56,0x15,0x56,
0x6F,0x87,0xBA,0x69,0x3C,0x33,0xF1,0x4B,
0xDB,0xB5,0xB9,0x9B,0xA2,0x8A,0xD7,0x1E,
0x18,0x5D,0x19,0x4C,0xF6,0xA9,0x24,0xAB,
0xFC,0x40,0x0C,0x91,0x54,0x65,0xBC,0x81,
0x97,0x1B,0xF6,0xB0,0xE0,0xAB,0x70,0x6B,
0x96,0xBC,0x9C,0x9D,0xCD,0x69,0xC1,0x45,
0x58,0xAF,0x24,0xC3,0x27,0x91,0xF9,0xD4,
0x46,0x72,0x09,0xC5,0x63,0x74,0x37,0xB8,
0xD3,0x71,0xF2,0xFB,0xD4,0x32,0x5C,0x0D,
0xDD,0xC6,0x4D,0x30,0x44,0x4D,0x70,0x37,
0x67,0x9A,0x8D,0xEE,0x14,0xFA,0xFE,0x55,
0x56,0xD4,0x5A,0x0C,0x13,0x64,0xD3,0xC3,
0x93,0xEB,0xCF,0x35,0x76,0x02,0x78,0x24,
0x2A,0x46,0x4E,0x07,0xB9,0xAE,0xBB,0xE1,
0xDD,0xD8,0x17,0xEC,0x13,0x2C,0x00,0xE4,
0x8A,0xD6,0x96,0xF7                    ,
0x13,0x3B,0x98,0xEE,0x59,0x87,0xB5,0x4D,
0x1C,0xCC,0x47,0x19,0xE6,0xBB,0x6F,0x7D,
0x08,0x48,0x9E,0x37,0x39,0xCF,0x35,0x2C,
0x72,0x1E,0xD4,0x9B                    ,
0x2D,0x23,0x29,0x03,0x80,0x3A,0xF1,0x4E,
0x55,0x6C,0x93,0xCD,0x73,0xF9,0x9A,0xB5,
0xD5,0x0F,0xDA,0xDF,0xED,0x7E,0x14,0x15,
0x23,0x83,0x9A,0x87,0xA8,0xBC,0xC6,0x30,
0x38,0xEF,0x50,0xBA,0xB6,0x7B,0xD6,0x52,
0x6D,0x01,0x1B,0x06,0xDA,0x41,0xC9,0xCF,
0xA8,0xAC,0x8D,0x5F,0x47,0xB1,0xBB,0xCF,
0xDA,0x2D,0x95,0x8F,0xF7,0xB1,0x83,0x58,
0xCA,0xF7,0xBA,0x29,0x5A,0xC7,0x3B,0x7F,
0xE0,0xEB,0x72,0x49,0xB6,0x9A,0x78,0x4F,
0x60,0x0E,0x45,0x64,0x5D,0xF8,0x53,0x55,
0x43,0x98,0x2F,0xCB,0x7A,0x07,0x5A,0x4D,
0xDF,0x74,0x0E,0x37,0xD8,0xCF,0xBB,0xD0,
0x7C,0x49,0x1F,0xDC,0x31,0x38,0x1D,0xF1,
0x8A,0xCF,0x9B,0x4B,0xF1,0x4A,0x93,0x8B,
0x65,0x61,0x9E,0xC6,0x9D,0xE2,0x4B,0x8B,
0x44,0x23,0x4D,0xF1,0x41,0xEB,0x66,0xB9,
0x3F,0xED,0x54,0xD6,0xFA,0x3F,0x89,0x1C,
0x61,0xAD,0xE3,0x5C,0xFA,0xB5,0x5A,0xB2,
0xEA,0x2E,0x57,0xD8,0xBF,0x6D,0xE1,0xDD,
0x7D,0xF8,0x67,0x82,0x3C,0xFD,0x4D,0x69,
0xD9,0x78,0x3E,0xFD,0xD8,0x19,0xB5,0x25,
0x51,0xDF,0x62,0xD1                    ,
0x74,0xBA,0x0D,0x41,0xEC,0xCD,0xAD,0x3B,
0xC1,0x76,0x0A,0xE0,0xDC,0x4B,0x34,0xEC,
0x39,0xC3,0x36,0x05,0x75,0x1A,0x55,0x8D,
0xAD,0x94,0x62,0x3B,0x78,0x56,0x30,0x3D,
0x05,0x5C,0x26,0xE4,0xD2,0x1F,0x2A,0x48,
0xD2,0x88,0x9D,0xC2,0xAC,0x26,0x71,0x9C,
0x8A,0xEC,0x4F,0x43,0x3B,0x13,0x47,0x92,
0x06,0x69,0xF9,0xC7,0x38,0x34,0xD0,0xD6,
0xDA,0x0E,0x8E,0x25,0x6C,0x64,0x71,0x53,
0xC7,0x6E,0x87,0xF8,0x6B,0x26,0x5B,0x69,
0x93,0x47,0x6B,0x1E,0x08,0x2B,0x52,0x7D,
0x8E,0x26,0xFE,0x1A,0x87,0x66,0x0D,0xE8,
0x28,0xD3,0xE0,0x60,0x3E,0x5C,0x7B,0xD2,
0x8D,0x2E,0x02,0x72,0x47,0x6F,0x4A,0x1C,
0x53,0x5A,0x93,0x70,0x1A,0x4C,0x07,0xE8,
0x7A,0xF1,0x4D,0x6D,0x12,0xDC,0xFA,0x56,
0x12,0x85,0x98,0xD3,0xB6,0x84,0x67,0x41,
0xB7,0x24,0xF0,0x05,0x31,0xFC,0x39,0x03,
0x0C,0x70,0x69,0x72,0x5B,0x61,0xF3,0x0C,
0x7F,0x0C,0xC0,0x46,0x30,0x2A,0x26,0xF0,
0xB4,0x39,0xE8,0x30,0x7D,0xA8,0xE4,0x4B,
0x71,0xA9,0x77,0x18,0xDE,0x16,0x87,0xA6,
0x14,0xE2,0x98,0x7C,0x27,0x16,0x49,0x0A,
0xBE,0x9D,0x29,0xF2,0xD8,0x7C,0xCC,0x69,
0xF0,0x9A,0xE7,0x85,0x5A,0x3F,0xE1,0x16,
0x2B,0x9C,0x0C,0x51,0xCA,0xC3,0x98,0x72,
0x78,0x71,0xD7,0xA0,0xFC,0x29,0xE7,0x41,
0x98,0x74,0x15,0x70,0x8B,0x4C,0x2F,0xDC,
0x55,0xD1,0xA6,0x03,0xEE,0x93,0x8F,0x4A,
0x72,0xE9,0x93,0x28,0xE5,0x4E,0x3D,0xAB,
0xA5,0x33,0x34,0x87,0x0B,0x19,0x46,0x32,
0x09,0x02,0x97,0xEC,0xB2,0x77,0x52,0x3F,
0x0A,0xA4,0xC1,0x1F,0xFF,0xD9
};

const  uint8_t image2[IMAGE2_SIZE] = {

/* Video Frame 2 */
0xFF,0xD8,0xFF,0xE0,0x00,0x21,0x41,0x56,
0x49,0x31,0x00,0x01,0x01,0x01,0x00,0x78,
0x00,0x78,0x00,0x00,0x00,0x00,0x00,0x00,
0x00,0x00,0x00,0x00,0x00,0x00,0x00,0x00,
0x00,0x00,   0x00,0x00,0x00,0xFF,0xDB,0x00,
0x43,0x00,0x04,0x02,0x03,0x03,0x03,0x02,
0x04,0x03,0x03,0x03,0x04,0x04,0x04,0x04,
0x06,0x0A,0x06,0x06,0x05,0x05,0x06,0x0C,
0x08,0x09,0x07,0x0A,0x0E,0x0C,0x0F,0x0F,
0x0E,0x0C,0x0E,0x0F,0x10,0x12,0x17,0x13,
0x10,0x11,0x15,0x11,0x0D,0x0E,0x14,0x1A,
0x14,0x15,0x17,0x18,0x19,0x1A,0x19,0x0F,
0x13,0x1C,0x1E,0x1C,0x19,0x1E,0x17,0x19,
0x19,0x18,0xFF,0xDB,0x00,0x43,0x01,0x04,
0x04,0x04,0x06,0x05,0x06,0x0B,0x06,0x06,
0x0B,0x18,0x10,0x0E,0x10,0x18,0x18,0x18,
0x18,0x18,0x18,0x18,0x18,0x18,0x18,0x18,
0x18,0x18,0x18,0x18,0x18,0x18,0x18,0x18,
0x18,0x18,0x18,0x18,0x18,0x18,0x18,0x18,
0x18,0x18,0x18,0x18,0x18,0x18,0x18,0x18,
0x18,0x18,0x18,0x18,0x18,0x18,0x18,0x18,
0x18,0x18,0x18,0x18,0x18,0x18,0x18,0xFF,
0xC0,0x00,0x11,0x08,
0x00,0x90,0x00,0xB0,0x03,0x01,0x21,0x00,
0x02,0x11,0x01,0x03,0x11,0x01,0xFF,0xDA,
0x00,0x0C,0x03,0x01,0x00,0x02,0x11,0x03,
0x11,0x00,0x3F,0x00,0xCA,0xB4,0x7C,0x1E,
0xF8,0xF4,0xAD,0x3B,0x56,0xE8,0x79,0xAF,
0x61,0x19,0x49,0xF7,0x34,0x6D,0xDB,0x24,
0x72,0x6A,0xF5,0xB1,0xF9,0x70,0x2A,0xBC,
0x91,0x0D,0xF6,0x2E,0xC0,0xE3,0x68,0x3C,
0xD5,0xB8,0x9C,0x63,0x0D,0x4A,0xEF,0x61,
0x58,0xB1,0x0C,0xA0,0x0C,0x92,0x31,0xEB,
0x4A,0xFA,0xA5,0xB4,0x6D,0xB5,0xA4,0x07,
0xDB,0xAD,0x4C,0xE6,0xA2,0xAE,0xC7,0x18,
0xB6,0xEC,0x91,0x62,0x1D,0x4A,0xC3,0xCA,
0xDF,0x2D,0xCA,0x27,0xA0,0xEA,0x6A,0x1B,
0x8D,0x72,0xC6,0x08,0x43,0x89,0x4B,0x03,
0xD0,0xED,0xAF,0x3A,0xAE,0x69,0x4E,0x0E,
0xDB,0x9D,0x94,0xF0,0x53,0x92,0xBB,0xD0,
0xA1,0x37,0x8A,0xED,0x41,0xCA,0x29,0x34,
0xC7,0xF1,0x85,0xAE,0xF1,0x98,0xDB,0x15,
0xCF,0xFD,0xB1,0x14,0xF6,0x36,0xFA,0x87,
0x99,0x62,0xDF,0xC6,0x3A,0x71,0x38,0x91,
0x8A,0x02,0x7D,0x33,0x5A,0xBA,0x7E,0xBB,
0xA2,0xDC,0x44,0x59,
0x75,0x08,0xD1,0xBA,0x6D,0x7E,0x33,0x5A,
0x47,0x36,0x81,0x0F,0x02,0xF6,0xB9,0x7E,
0xE4,0x43,0x1D,0xA8,0xB8,0x8E,0xFA,0xDA,
0x44,0x61,0x9C,0x47,0x20,0x24,0x7E,0x15,
0x56,0x3B,0xD8,0xE5,0x19,0x59,0x97,0x1F,
0x5A,0xEF,0xA1,0x8A,0xA7,0x57,0x66,0x72,
0xD5,0xC3,0x4E,0x9E,0xAC,0x70,0x94,0x93,
0x95,0x39,0x06,0xA3,0x95,0xCE,0xFC,0x70,
0x09,0xAE,0xA4,0x60,0x41,0x33,0x30,0xC8,
0xC8,0xC7,0x6A,0x82,0x42,0x02,0xE0,0xE4,
0x55,0x2F,0x21,0xAB,0xA2,0xAC,0xAF,0xF3,
0x71,0xC5,0x53,0x99,0x86,0x0F,0xBF,0xAD,
0x57,0xA1,0x57,0x57,
0x3C,0xEE,0xD9,0x87,0x18,0x3C,0xD6,0x95,
0xAB,0x9C,0x01,0xD6,0xB9,0x79,0xBB,0x96,
0xDD,0xCD,0x08,0x1F,0x9A,0xBB,0x6E,0xFC,
0x67,0x22,0xAB,0x98,0x86,0x8B,0x96,0xF2,
0x70,0x33,0xDE,0xAC,0xA4,0xB8,0x3D,0x73,
0x49,0xB2,0x75,0x2A,0xDF,0xDD,0xB1,0x62,
0xAA,0x78,0xFC,0xAA,0x88,0xB9,0x41,0x03,
0xA3,0xC7,0x97,0x6E,0x8D,0x9E,0x95,0xF2,
0xB9,0x96,0x32,0x53,0x9B,0x8A,0x7A,0x1E,
0xE6,0x12,0x82,0x84,0x53,0x7B,0x8D,0x36,
0xBB,0xF4,0x56,0xBD,0x32,0x31,0x60,0xD8,
0xDB,0x8A,0xA2,0xF2,0x3B,0x28,0x42,0xC4,
0xA8,0xE8,0x2B,0xCA,0x55,0x2E,0xF5,0x3B,
0x6D,0x62,0x26,0x18,0x63,0xC5,0x43,0x2E,
0x73,0xDE,0x9F,0x36,0x82,0x22,0x7F,0xBC,
0x38,0xA6,0xC6,0x76,0xB8,0x20,0x67,0x15,
0x5C,0xDD,0x40,0x70,0xB8,0x99,0x58,0xED,
0x76,0x51,0xEC,0x6A,0xDD,0x96,0xAB,0x79,
0x0B,0x02,0xB3,0x36,0x07,0x63,0x5A,0xC2,
0xAC,0xA2,0xEE,0x89,0x94,0x53,0xDC,0xE9,
0x34,0x6F,0x13,0x87,0x22,0x3B,0xA4,0xC6,
0x7F,0x88,0x57,0x40,0x97,0x22,0x48,0x84,
0x80,0xA9,0x53,0xD2,
0xBE,0x8F,0x2D,0xC6,0xBA,0xBE,0xE4,0xB7,
0x3C,0x9C,0x66,0x19,0x47,0xDE,0x43,0x26,
0x9B,0x2B,0x9D,0xC3,0x9E,0x82,0xAB,0xBC,
0xA3,0x19,0x38,0x27,0xD2,0xBD,0x94,0xEE,
0x79,0xF7,0x2B,0xCD,0x2E,0x40,0xAA,0x93,
0xBF,0x1E,0xD4,0xD3,
0x63,0x6F,0xA1,0xE7,0x56,0xB2,0x7C,0xA3,
0x9C,0xD6,0x85,0x9C,0xB8,0x60,0x33,0xD6,
0xB9,0xAF,0x7D,0x0B,0x7B,0x1A,0x16,0xF2,
0x73,0xC9,0xC5,0x5C,0x82,0x4E,0x39,0x3D,
0xE9,0xDF,0xA1,0x0D,0xDC,0xB7,0x1C,0xBE,
0x86,0xA6,0x13,0x7C,0x99,0x26,0xA6,0x5B,
0x09,0x3D,0x4A,0xB2,0xB1,0x2E,0x4E,0x6A,
0xB4,0xA7,0xAF,0x1C,0x1A,0xF8,0x9C,0x57,
0xF1,0x59,0xF4,0x94,0xBE,0x04,0x02,0xE6,
0x65,0xB5,0x36,0xEA,0xC7,0xCB,0x63,0xC8,
0xC5,0x36,0xD5,0x8D,0xBD,0xDC,0x72,0xBC,
0x61,0xC2,0x90,0xDB,0x4F,0x43,0x5C,0xFA,
0x1A,0xDC,0x5D,0x56,0x75,0xBB,0xBE,0x79,
0xD6,0x24,0x89,0x5F,0x1F,0x2A,0xF0,0x07,
0x15,0x4A,0x41,0xF3,0x9C,0xE7,0x14,0x45,
0x59,0x58,0x1B,0x4F,0x52,0x09,0x31,0xBB,
0xDE,0x9D,0x77,0x0A,0xC4,0x54,0xA4,0xAA,
0xE1,0x86,0x78,0xED,0x54,0xE4,0xD6,0x82,
0x20,0x6C,0x6D,0x3D,0x29,0x53,0xA8,0xFD,
0x4E,0x69,0xA7,0x60,0xF3,0x2D,0x5A,0xF0,
0xE2,0xBA,0xCD,0x0E,0x63,0xF6,0x00,0xAC,
0xC7,0x1D,0xAB,0xD6,0xCA,0x9F,0xEF,0x91,
0xC5,0x8D,0xB7,0xB3,0x65,0xB3,0x28,0x2B,
0x8C,0x11,0x51,0x99,0x32,0x49,0xEB,0x5F,
0x58,0xAC,0xCF,0x0E,0xE4,0x13,0xCA,0x73,
0x8E,0x9F,0x5A,0xA7,0x73,0x27,0xCD,0xCF,
0x4A,0x63,0xD4,0xF3,0xCB,0x76,0xC1,0x3C,
0x9A,0xBF,0x6C,0xDC,0x0C,0xD6,0x1D,0x0D,
0x1A,0xB9,0x7A,0xD9,0xF8,0x06,0xAE,0xC4,
0xFF,0x00,0x2E,0x7D,0x3B,0x52,0x6C,0xCD,
0x96,0x6D,0xE4,0xC0,0xEB,0x52,0x5C,0xDC,
0x88,0x6C,0xE4,0x9B,0xA8,0x41,0x9E,0xB5,
0x32,0x12,0xD1,0x9C,0x5E,0x85,0xE3,0xC8,
0x6E,0xF5,0xA7,0xB1,0xBA,0x8C,0x46,0x4B,
0x10,0xAC,0x3A,0x57,0x5A,0x70,0xC3,0x70,
0xC1,0x04,0x67,0x8A,0xF9,0x1C,0x7D,0x27,
0x4E,0xA5,0xCF,0x7B,0x09,0x5B,0x9E,0x36,
0xEC,0x30,0x1C,0x30,0x3E,0x9E,0xB5,0x25,
0xF5,0xC3,0x5C,0x48,0xAC,0x40,0x5D,0xA3,
0x1C,0x57,0x9F,0x6D,0x6E,0x75,0xA6,0x58,
0xD4,0x34,0x99,0xED,0x74,0x7B,0x5D,0x46,
0x46,0x43,0x1D,0xDF,0x28,0x01,0xC9,0x1C,
0x67,0x91,0x59,0x92,0x03,0x9F,0x5A,0x23,
0x2B,0xEA,0x84,0xD5,0x8A,0xEE,0xB9,0x38,
0xE4,0xD3,0x08,0xE7,0xAF,0x4E,0x2A,0xEE,
0x24,0xC6,0x91,0xCF,0xD6,0x9E,0xAB,0x82,
0x2A,0x95,0xBA,0x8D,0x16,0x2D,0xB2,0x18,
0x57,0x4B,0xA2,0xB6,0x2D,0x02,0x8A,0xF5,
0x72,0xAF,0xE3,0x1C,0x58,0xDB,0xFB,0x36,
0x58,0x77,0xC6,0x46,0x79,0x15,0x0B,0xC9,
0xF2,0xE7,0x90,0x4D,0x7D,0x62,0x3C,0x26,
0xC8,0x64,0x6C,0x9C,0x67,0x3C,0x55,0x69,
0xA4,0x00,0x62,0x85,
0x72,0xD3,0x3C,0xF2,0xD9,0x8E,0x07,0x5A,
0xBD,0x6E,0xFD,0x38,0xEB,0x58,0x22,0xDE,
0xFA,0x97,0xE0,0x7C,0x03,0x57,0x20,0x90,
0x9C,0x73,0xCD,0x3F,0x52,0x19,0x6A,0x29,
0x0E,0xDE,0xB4,0x97,0xCA,0x66,0xB1,0x92,
0x10,0xD8,0x2E,0xB8,0xA9,0x97,0x72,0x52,
0x77,0x38,0xCB,0xAF,0x87,0x6A,0x41,0xBA,
0xB7,0xB8,0x63,0x73,0xBB,0x72,0xE4,0xF0,
0x2B,0xA1,0xB6,0xB6,0xD6,0xA2,0xB2,0x48,
0xCC,0xD1,0x06,0x8D,0x71,0xD3,0xAD,0x7C,
0x9E,0x32,0xBA,0xA9,0x26,0xA4,0x7B,0xB8,
0x7A,0x2E,0x09,0x38,0xBD,0xCA,0xB3,0xEB,
0x77,0x16,0x31,0xED,0xBE,0xB6,0xCC,0x83,
0xA6,0xD3,0x8C,0x8F,0xA5,0x6A,0x78,0x67,
0x53,0x87,0x50,0xB3,0x99,0xE6,0xB4,0x9A,
0x16,0xC6,0x13,0x78,0xAE,0x29,0xD3,0xB4,
0x5B,0x8B,0x36,0x55,0x1D,0xD4,0x59,0xAB,
0x73,0x73,0x79,0x75,0xA6,0xC5,0x0B,0xE4,
0xC1,0x6D,0xF2,0xAF,0xB7,0x6A,0xCF,0x90,
0x65,0xAB,0x28,0x24,0xB6,0x36,0x91,0x13,
0x0C,0x1E,0x29,0x98,0x24,0x74,0xAB,0x4B,
0xB1,0x37,0x1A,0xE3,0xA7,0xB5,0x39,0x54,
0xE0,0x1E,0xF8,0xAA,
0x40,0x99,0x34,0x03,0x9F,0x71,0x5B,0xFA,
0x63,0xEC,0xB6,0x1C,0xD7,0xAD,0x94,0xAF,
0xDE,0x9C,0x78,0xEF,0xE1,0xB2,0x47,0x70,
0x64,0x38,0x27,0x04,0x71,0x50,0x4C,0xF8,
0x6E,0x4F,0xEB,0x5F,0x52,0x78,0x77,0x21,
0x79,0x40,0xE9,0x9F,0x7A,0xAF,0x2B,0x75,
0x39,0xC6,0x79,0xAA,
0x5D,0x8A,0x3C,0xFE,0xD9,0xB9,0xAB,0xD6,
0xED,0x58,0x2F,0x33,0x46,0x5E,0x81,0xB8,
0x19,0xAB,0x70,0xF0,0x49,0xC0,0xFC,0xAA,
0x9D,0x8C,0xEE,0x5A,0x83,0x21,0xF9,0xC7,
0x1E,0x95,0x38,0x60,0xA7,0x73,0x10,0x00,
0xE4,0x9A,0x89,0x3B,0xA1,0x27,0xA9,0x3D,
0x85,0xE5,0xB5,0xD2,0x31,0x8A,0x40,0xC1,
0x78,0xEB,0x59,0xDE,0x21,0xD6,0xAD,0x74,
0xE4,0xE5,0x84,0x92,0x1E,0x88,0x0D,0x7C,
0x5D,0x58,0x4A,0x55,0x1A,0x3E,0x92,0x12,
0x51,0x82,0x67,0x25,0x71,0x7E,0xBA,0x96,
0xAB,0x1D,0xD4,0xA0,0x20,0x88,0xE7,0x60,
0xEE,0x3F,0x1A,0xEA,0x74,0x5D,0x4E,0xD6,
0xFA,0x43,0x0C,0x11,0xB8,0xD9,0xC1,0x38,
0xC0,0xA7,0x52,0x9B,0x4A,0xCB,0xA1,0x9C,
0x2A,0x2E,0x6B,0xF7,0x35,0x96,0x46,0x58,
0x4C,0x63,0x3B,0x4D,0x41,0x20,0xE7,0x38,
0xFA,0x57,0x35,0xBA,0xB3,0xA1,0xB2,0x19,
0x17,0x8C,0xD4,0x61,0x78,0x3D,0x05,0x3B,
0x68,0x2B,0xDF,0x71,0xAC,0xA3,0x3D,0x05,
0x3D,0x14,0x63,0xA0,0x02,0xA9,0x5C,0x09,
0xED,0xD4,0x64,0x70,0x2B,0x5A,0x02,0x56,
0xDC,0x63,0x8A,0xF5,
0xB2,0xAB,0xFB,0x63,0x8B,0x1D,0xFC,0x3D,
0x05,0x76,0x04,0x0E,0x73,0xE9,0x8A,0x8E,
0x56,0xC0,0xE0,0xFE,0x75,0xF5,0x29,0x58,
0xF1,0x2C,0x57,0x90,0xF2,0x39,0xC1,0xEF,
0x55,0xE7,0x6D,0xA4,0x7C,0xD9,0xA6,0x86,
0x8E,0x06,0xD9,0xBE,0x9C,0x55,0xC8,0x0F,
0x23,0xBF,0xA5,0x60,0x99,0xAC,0x91,0x7A,
0xDC,0xF3,0xC9,0xAB,0x70,0x31,0xF5,0x23,
0x1E,0xF5,0x57,0x33,0x7B,0x68,0x5A,0x85,
0xFB,0x66,0xA1,0xD7,0x1C,0xA6,0x91,0x39,
0xDD,0x8F,0x90,0x9E,0xB5,0x2D,0x2D,0x49,
0x47,0x29,0xE0,0xBD,0x45,0x20,0xF0,0xAD,
0xFD,0xD4,0xD7,0x05,0x42,0x31,0x50,0x77,
0x13,0x57,0x3E,0x1A,0xD9,0xDA,0x6B,0x30,
0x5C,0x5E,0x5C,0x28,0x95,0x37,0x61,0x59,
0xAB,0xE6,0x31,0x37,0x53,0x9C,0x91,0xEE,
0x53,0xB5,0xA2,0x99,0xB4,0xC3,0x45,0x82,
0x42,0x20,0xB1,0x69,0x55,0x0F,0x2E,0x8B,
0xC5,0x49,0x0E,0xBB,0xA5,0x5B,0xC2,0x1E,
0x08,0x5C,0x21,0x6D,0xA7,0x0B,0x8C,0x1F,
0x7A,0xE0,0x71,0x9C,0xF7,0x66,0xDC,0xD1,
0x89,0x66,0xEB,0x5A,0xB6,0x86,0xF6,0x2B,
0x73,0x1C,0x85,0xE5,0x1B,0x94,0x01,0x9E,
0x2A,0x17,0xF1,0x15,0x97,0x9B,0x24,0x02,
0x19,0x4B,0xC7,0xF7,0xB0,0xB5,0x2A,0x8B,
0x63,0x95,0x54,0x86,0x5C,0x6B,0xDA,0x74,
0x56,0xE2,0x66,0x76,0x2A,0x4E,0x08,0x0B,
0xC8,0x3E,0x84,0x53,
0xAD,0xB5,0x6B,0x2B,0x99,0x04,0x69,0x21,
0x57,0x3C,0x80,0xC3,0x19,0xAA,0xF6,0x32,
0xDC,0x7E,0xD2,0x23,0x1B,0x58,0xD3,0x44,
0xAD,0x11,0xB9,0x01,0x93,0x82,0x31,0xD2,
0xAD,0xAD,0xDD,0xA6,0xD4,0x26,0xE2,0x3C,
0x38,0xC8,0xE6,0x92,0x84,0x96,0xB6,0x2B,
0x9D,0x3D,0x0B,0x96,0xCC,0x85,0xC0,0x0C,
0xA4,0x9E,0x7A,0xD6,0x80,0x6D,0xAA,0x16,
0xBD,0x5C,0xA9,0x7E,0xF4,0xE4,0xC7,0x3F,
0xDD,0x8D,0x67,0x0B,0xD0,0xE3,0xDE,0xA2,
0x94,0xE5,0x4E,0xE3,0x9F,0x4C,0x57,0xD3,
0xDD,0x9E,0x22,0x2B,0xBB,0x02,0xA3,0x8A,
0x82,0x76,0xE3,0xD7,0x14,0xF9,0x8B,0x4F,
0xB1,0xC0,0xDB,0x1E,0x9C,0xF1,0x57,0x60,
0xCE,0x3A,0xD7,0x3A,0xD4,0xD2,0x4B,0xB1,
0x76,0xD8,0x9C,0x7F,0x8D,0x5D,0x89,0xB8,
0x07,0x8A,0xA6,0xCC,0xDA,0x2C,0x42,0xFC,
0xFB,0x83,0x50,0x78,0x95,0xBF,0xE2,0x43,
0x72,0x73,0xCE,0xC3,0x43,0x6A,0xC4,0x27,
0x63,0xCC,0x35,0x6F,0x3A,0xD7,0xC2,0xB0,
0x69,0xB1,0x86,0x69,0x6F,0x64,0x32,0x1C,
0x0F,0x5E,0x95,0xE9,0xDE,0x14,0xD2,0xDB,
0x45,0xF0,0x02,0x40,0x46,0xD9,0x1D,0x46,
0xE3,0xF5,0xEB,0x5F,0x31,0x8D,0x9A,0x49,
0xAE,0xEC,0xF6,0xA8,0x2B,0xC9,0x79,0x23,
0xA1,0xD2,0x6D,0xE1,0x4D,0x36,0x35,0x44,
0x5C,0x32,0xE4,0xFB,0xD5,0x3B,0xBD,0x12,
0x01,0xA7,0x5C,0x2C,0x4A,0x01,0x6F,0x9F,
0xF1,0xAF,0x2D,0xC9,0xA6,0x76,0x72,0xA7,
0x14,0x65,0x78,0x22,0x09,0xEE,0xE4,0x92,
0xF6,0xF0,0x02,0xF1,0x93,0x1A,0xFD,0x07,
0x4A,0x86,0xCE,0xFA,0x0B,0x6D,0x7E,0xFC,
0x3C,0x4E,0xE7,0x3F,0xC2,0xB9,0xAD,0xBE,
0x29,0xB4,0xBB,0x18,0xA5,0x68,0xDC,0xCB,
0xD6,0xE1,0x91,0x56,0x4B,0xEF,0xB3,0x15,
0x8E,0x49,0x06,0xD8,0xF1,0xD6,0xAD,0xDE,
0xDC,0xAD,0xDE,0xA1,
0x69,0x6A,0xB6,0x8D,0x6F,0x26,0x43,0x07,
0x23,0x15,0xA5,0xAF,0x6D,0x76,0x15,0xF5,
0xBD,0x88,0x21,0xB8,0xB7,0x87,0x5D,0xBC,
0x86,0x5B,0x36,0x97,0x7B,0x85,0xDC,0x17,
0x22,0xAD,0xDD,0xDB,0x5A,0xDA,0xDF,0xB2,
0xDD,0x42,0xFF,0x00,0x67,0x91,0x30,0x8E,
0x06,0x42,0x1A,0x1D,0xEE,0x9D,0xC7,0xA6,
0xBA,0x16,0x74,0x4B,0x64,0x5D,0x45,0x50,
0xCE,0xE2,0x44,0x20,0xC6,0xC4,0xF0,0xEB,
0x5D,0x4C,0xB9,0x24,0x60,0xF4,0xED,0x5E,
0x96,0x5D,0x2F,0xDE,0x1C,0xD8,0xB4,0xBD,
0x9B,0xB0,0xC9,0x98,0x1E,0x73,0x55,0xDE,
0x43,0xB7,0xDF,0xEB,0x5F,0x42,0xA5,0xA6,
0xA7,0x92,0x88,0x9D,0xC6,0x6A,0x09,0x64,
0xE3,0xB1,0xCD,0x3B,
0xF5,0x29,0x2B,0x1C,0x0D,0x93,0xEE,0x88,
0x1F,0x6C,0xD6,0x84,0x0F,0x80,0x39,0xEB,
0x58,0x45,0xE8,0x6D,0x51,0x6A,0xD2,0x2D,
0xC0,0xDC,0x74,0xAB,0x90,0x3F,0x1D,0x79,
0xAA,0x31,0x7B,0x16,0x23,0x62,0x0F,0xD6,
0xA3,0xD6,0xF3,0x26,0x95,0x34,0x60,0x12,
0x59,0x71,0x8A,0x25,0xB1,0x1D,0x4C,0xEF,
0x0E,0x78,0x5A,0x4B,0xFF,0x00,0x12,0x41,
0x7B,0x77,0x16,0xDB,0x7B,0x44,0x02,0x30,
0x47,0x53,0x5D,0xF6,0xA1,0x04,0x52,0x59,
0x3C,0x2E,0x42,0xA3,0x0C,0x7D,0x2B,0xE3,
0xF1,0x75,0x6F,0x3B,0x2E,0x87,0xD1,0x50,
0xA6,0xD2,0xBF,0x73,0x9E,0x49,0x75,0x5B,
0x45,0x36,0xD6,0xF7,0x10,0x3C,0x7F,0xC2,
0xEC,0x79,0x15,0x7E,0xCD,0xDE,0x1D,0x2A,
0x44,0x92,0xF1,0x25,0x99,0xC1,0xE4,0xB7,
0x7A,0xE7,0x9B,0x8B,0x57,0x5B,0x9A,0x2A,
0x73,0xBF,0x91,0x57,0xC2,0xE9,0x2D,0x95,
0x94,0x91,0xDC,0x49,0x09,0x66,0x62,0xC3,
0x69,0xA8,0x34,0x4B,0x79,0xA1,0xD5,0x6E,
0xA6,0xB9,0x30,0xEC,0x98,0xE5,0x48,0x35,
0x4E,0x71,0xBB,0x64,0xF2,0x4E,0xC9,0x09,
0xE2,0xE8,0x66,0xB9,
0x8E,0x04,0xB5,0x08,0xC1,0x1C,0x31,0xC9,
0xA6,0xEB,0x50,0xCD,0x2B,0xDA,0x4F,0x0C,
0x6A,0xC6,0x26,0x05,0x94,0x1E,0x69,0xC5,
0xA4,0x90,0x38,0x49,0xB6,0x67,0x59,0xBD,
0xED,0xBD,0xCD,0xDB,0xB6,0x9F,0xBB,0xCD,
0x60,0x54,0xE6,0x96,0x1B,0xDD,0x4B,0x12,
0xC3,0x7D,0x62,0xD2,0x09,0x46,0x10,0x8E,
0x71,0x5A,0x5A,0x2D,0xEE,0x45,0xE6,0xBA,
0x16,0xF4,0x63,0x3F,0x9B,0x05,0xA5,0xC5,
0xAB,0x2C,0xB1,0x30,0x21,0xF1,0xC6,0x2B,
0xA2,0xB8,0x91,0x77,0xE3,0xA6,0x2B,0xD4,
0xCB,0x5A,0xF6,0xBA,0x1C,0xB8,0xB6,0xFD,
0x9D,0x88,0x0C,0x9F,0x29,0x3C,0xF1,0x51,
0x79,0x8A,0x09,0xCB,0x75,0xAF,0xA0,0x4E,
0xE7,0x94,0x9D,0xD9,0x5E,0x66,0xC9,0x04,
0x1D,0xA4,0x54,0x12,0xB9,0xFE,0xF0,0xE6,
0x9D,0xCA,0x49,0x9C,0x55,0xAA,0xE1,0x40,
0xC6,0x31,0x57,0x61,0xE1,0x86,0x4D,0x64,
0x92,0x2A,0x4B,0x5D,0x4B,0x70,0x74,0xF6,
0xAB,0x51,0x3E,0x3E,0xB4,0xCC,0xE4,0x59,
0x85,0xB7,0x0F,0x71,0xEF,0x57,0x2D,0x02,
0xB4,0xC8,0xAC,0x01,0x07,0xB1,0xA5,0x53,
0x66,0x28,0xAD,0x4E,0x9E,0xC9,0x15,0x62,
0x00,0x00,0x30,0x29,0xD7,0x31,0xAC,0x89,
0xB5,0xC6,0x54,0xF6,0xAF,0x86,0xAB,0xF1,
0xB3,0xEA,0x23,0xB2,0x29,0x9D,0x3A,0xCF,
0xFE,0x79,0x0A,0xAB,0xA9,0x59,0xD8,0xDA,
0xD9,0xC9,0x70,0xF1,0xF0,0x83,0x38,0xCD,
0x47,0x31,0xA2,0x9C,0xB6,0x33,0x74,0x47,
0xB4,0xBF,0xB3,0x92,0xE0,0xDB,0x3C,0x6B,
0x1E,0x4F,0x3D,0xF1,0x51,0xE8,0xA6,0xD7,
0x53,0x96,0x40,0x90,0xBA,0x22,0x12,0x37,
0x67,0xAD,0x5E,0xBD,0xCD,0x9A,0x92,0xBA,
0xBE,0xC5,0x67,0xB9,0xD3,0xCE,0xBA,0x74,
0xD0,0x92,0x17,0x1D,0x48,0x34,0xFD,0x5C,
0x58,0xD9,0x5E,0x43,0x6C,0xC6,0x52,0xF3,
0x1C,0x00,0x0D,0x55,0xDE,0x82,0xF7,0xB4,
0xF3,0x17,0x50,0x82,0xDA,0xD3,0x6A,0xEF,
0x95,0x9D,0xB9,0x0A,0x0D,0x32,0x71,0x6B,
0x06,0x9E,0xB7,0x4D,0x73,0x22,0xA3,0x1D,
0xA0,0x13,0xDF,0x34,0x2B,0xEF,0x62,0x6E,
0xDE,0xB6,0x2F,0xD8,0x08,0x62,0xBE,0x89,
0x3E,0xD6,0xC5,0xDC,0x64,0x2B,0x77,0x15,
0x72,0xFF,0x00,0xFD,0x69,0xE4,0x66,0xBD,
0x8C,0xAB,0xF8,0x8C,0xF3,0x73,0x25,0xEE,
0x5D,0x95,0x64,0x7E,0x33,0x9F,0xD6,0xA2,
0x77,0xDA,0xC4,0x9C,0x11,0x8A,0xFA,0x24,
0x8F,0x09,0x32,0xBB,0x49,0x90,0x79,0x15,
0x1C,0xAF,0x81,0x4C,
0xB5,0xE6,0x72,0xB6,0xE7,0xF2,0xAB,0x50,
0x8C,0xE3,0xD6,0xB2,0x4C,0xD6,0x77,0xEA,
0x5A,0x80,0x80,0x71,0xDA,0xAC,0x46,0xDC,
0x01,0xCF,0xD7,0x34,0xDB,0x32,0x65,0x98,
0x1F,0x91,0x8A,0xBB,0xA6,0x30,0x6B,0xB4,
0x1E,0xA6,0xA6,0x6F,0xDD,0x64,0xA5,0xA9,
0xD6,0xDB,0x8F,0xDD,0x03,0x8C,0xE0,0x54,
0xA5,0x72,0xBF,0xFD,0x6A,0xF8,0x8A,0x8F,
0xDE,0x67,0xD3,0xC2,0xFC,0xA8,0x8A,0x45,
0x00,0xFA,0x0A,0xAF,0x7B,0x6F,0x1D,0xC4,
0x06,0x29,0x46,0x55,0xAA,0x4A,0x4E,0xC4,
0x66,0xCE,0x25,0xB2,0x6B,0x64,0x5D,0xA8,
0x46,0xDE,0x2A,0xA6,0x8F,0xA5,0x47,0xA7,
0x46,0xCB,0x1B,0x92,
0x18,0xE6,0x9C,0x5E,0x83,0xF6,0x8E,0xCD,
0x77,0x2B,0xC5,0xA1,0x5B,0x45,0xAA,0xB6,
0xA0,0xA4,0xF9,0xA4,0xF3,0x4F,0x9F,0x4D,
0x86,0x5D,0x49,0x6F,0x24,0x1B,0x99,0x46,
0x06,0x69,0xA6,0x0E,0xAB,0x76,0x7D,0x88,
0xF5,0x2D,0x27,0xED,0x97,0x09,0x32,0x4C,
0xD1,0x32,0x8C,0x12,0x3D,0x29,0x2F,0xF4,
0x4B,0x7B,0x8B,0x18,0xAD,0x8B,0x31,0x58,
0xDB,0x77,0xD4,0xD5,0x46,0xE8,0x6A,0xA5,
0x95,0x89,0xED,0xF4,0x68,0xA4,0xD6,0x23,
0xBC,0x2C,0xC6,0x48,0xC6,0xD0,0x3B,0x55,
0x7D,0x62,0x40,0x97,0x8E,0xA4,0xE0,0x83,
0x82,0x2B,0xD8,0xCA,0x9B,0xF6,0x9A,0x9E,
0x7E,0x63,0x37,0x3A,0x7A,0x94,0xA4,0x9C,
0x10,0x46,0x47,0x35,0x1B,0x48,0x08,0xC1,
0x38,0xAF,0xA1,0xB9,0xE2,0xA4,0x88,0x99,
0xF0,0xC0,0x06,0xCE,0x2A,0x19,0x9C,0x1F,
0x53,0xF8,0xD0,0x98,
0xED,0xA1,0xD2,0x2F,0xC3,0xDB,0xC2,0x32,
0x96,0x0C,0x07,0xFB,0x84,0x7F,0x5A,0x92,
0x3F,0x87,0xBA,0x96,0x08,0xFB,0x0B,0x7F,
0xDF,0x24,0xD7,0x93,0x1C,0x53,0xEA,0x7A,
0xD2,0xC1,0xA6,0x4F,0x0F,0xC3,0xBD,0x4C,
0xC9,0xCD,0x94,0x83,0x3F,0xEC,0x35,0x58,
0x97,0xC0,0x72,0xC0,0xD8,0x92,0xD2,0x52,
0x40,0xCF,0x19,0x15,0x4B,0x18,0xCC,0xDE,
0x11,0x1A,0x9A,0x07,0xC3,0x1F,0xED,0x18,
0x4C,0x99,0x78,0xB0,0x71,0xB4,0x92,0x6A,
0xED,0xCF,0xC2,0xF9,0x34,0xD8,0x1A,0xF3,
0xCE,0x2E,0x21,0x1B,0xB1,0x4A,0x58,0xD7,
0x66,0xAC,0x47,0xD5,0x15,0xCC,0xD8,0x61,
0x3C,0xA7,0x4C,0x71,0x59,0x5E,0x20,0xD7,
0x23,0xD2,0xA6,0x64,0x9A,0x12,0xC8,0xA0,
0x12,0xC2,0xBE,0x71,0xC7,0x9A,0x6C,0xF5,
0x6F,0xCB,0x0B,0x95,0x2C,0x3C,0x57,0x63,
0x76,0xA4,0xA4,0x72,0x00,0xA3,0x23,0x8E,
0xB5,0x2A,0xEB,0xB6,0x0D,0x2C,0x31,0xB3,
0x14,0x69,0x8E,0x10,0x1E,0x33,0x4A,0x54,
0x24,0x99,0x0A,0xAA,0x7A,0x9A,0x45,0x0E,
0x33,0xDA,0x98,0xC0,0x83,0x50,0x9D,0xB6,
0x35,0xF3,0x18,0xCA,0x79,0xEB,0xF4,0xA6,
0xC8,0x99,0x6F,0xAF,0xBD,0x32,0x50,0x14,
0xC2,0x60,0x0C,0x53,0x11,0x18,0x9F,0x7F,
0x4A,0xA4,0x3B,0x17,0xF4,0xE8,0x88,0x7D,
0xC4,0x53,0x6E,0x7C,0x16,0x6F,0xAE,0x1E,
0xE5,0xAE,0x19,0x77,0xF3,0x80,0x2B,0xAF,
0x0F,0x89,0xF6,0x13,0xE7,0xB1,0x9D,0x6A,
0x1E,0xDA,0x3C,0xAC,0x80,0x78,0x2F,0x4D,
0x49,0x76,0x4D,0xA9,0x61,0xC7,0x55,0x1D,
0x69,0x64,0xF0,0xBE,0x83,0x03,0x62,0x6B,
0xA9,0x9B,0x8E,0x9E,0xB5,0xDA,0xF3,0x69,
0xBD,0xA2,0x73,0xC7,0x2E,0x82,0xDD,0x93,
0x5B,0xE8,0xBE,0x19,0x5E,0x3C,0x89,0xE5,
0x3E,0xE0,0x9C,0xD4,0xEB,0x63,0xA1,0x46,
0xA0,0x47,0xA4,0xB9,0xFA,0xA9,0xAE,0x59,
0xE6,0x35,0xA5,0xD4,0xEA,0x86,0x0A,0x92,
0xE8,0x7B,0x3D,0xBE,0x95,0xC0,0xE0,0x0A,
0xB9,0x06,0x96,0x83,0xB0,0xAD,0xEE,0x53,
0x2D,0xC3,0xA6,0xA0,0x1C,0xA8,0x35,0x3A,
0x69,0xC9,0xC6,0x54,0x7D,0x71,0x49,0x36,
0x64,0xD1,0x34,0x76,0x31,0xA8,0xE1,0x47,
0xE0,0x2A,0x9F,0x89,0x6C,0x93,0xFB,0x12,
0xE0,0xE0,0x72,0xA6,0x89,0x3D,0x0C,0xFA,
0xEA,0x78,0xBD,0xDD,0x9F,0x91,0x73,0x27,
0x1C,0x67,0x8A,0xC3,0xD6,0xF4,0x4B,0x1B,
0xE9,0x19,0xAE,0x23,0x2C,0x58,0x60,0xF3,
0xD6,0xBC,0x97,0x36,0xA5,0x74,0x75,0xB8,
0xDD,0x59,0x99,0x91,0x78,0x4E,0xC2,0x12,
0xC2,0x12,0xEA,0x18,0x74,0xCF,0x4A,0xAB,
0x73,0xE0,0xFB,0x79,0x66,0x86,0x46,0xBA,
0x94,0xB4,0x07,0x29,0xF5,0xAD,0x16,0x22,
0x57,0xBB,0x31,0x74,0x15,0xAD,0x73,0x7C,
0x21,0x48,0x15,0x09,0x27,0x68,0xC5,0x43,
0xB7,0x24,0xD6,0x57,0xD4,0xD5,0x46,0xDA,
0x0D,0x3C,0x1A,0x43,0x8C,0xF1,0x4D,0x0E,
0xC1,0xC6,0x69,0xF1,0x26,0x08,0x38,0xEA,
0x6A,0x90,0x8D,0xCD,0x22,0xCB,0xED,0x45,
0x63,0x19,0x19,0x35,0xEC,0x7A,0x1F,0x85,
0x6D,0x97,0x48,0x87,
0xF7,0x4A,0xCC,0x50,0x64,0x9F,0xA5,0x74,
0x52,0x49,0xB1,0x4F,0x6D,0x0E,0x5F,0x51,
0xF8,0x56,0xE7,0x5B,0x9B,0x51,0xB5,0xB9,
0x0A,0xF2,0x1C,0x88,0xC8,0xE0,0x7D,0x2A,
0x9E,0xA3,0xE0,0x2F,0x10,0x6E,0xC9,0x82,
0x19,0x42,0xF0,0x31,0x8C,0xD2,0xA9,0x07,
0x7D,0x0B,0x84,0x97,0x52,0x9A,0xF8,0x4F,
0x5E,0x81,0xB0,0xDA,0x36,0x40,0xEA,0x40,
0xA4,0x93,0xC3,0x1A,0xB1,0x39,0x6D,0x20,
0x80,0x7D,0x87,0xF8,0xD6,0x2E,0x9B,0x36,
0x53,0x47,0xA3,0xC6,0xD8,0x03,0x35,0x3C,
0x4C,0xB8,0xE4,0xD7,0xA0,0x9E,0x97,0x30,
0x68,0xB3,0x14,0x88,0x31,0xF3,0x54,0xAB,
0x2C,0x79,0xFB,0xC2,0x87,0x23,0x29,0x21,
0xEB,0x71,0x16,0x7E,0xF0,0xAA,0x5E,0x27,
0xB8,0x8B,0xFB,0x0E,0x71,0xBF,0x9C,0x54,
0xCA,0x5A,0x12,0xA3,0xA9,0xE3,0x9A,0xC1,
0x06,0x66,0xF4,0xAC,0x8B,0x8E,0xBC,0x0C,
0x66,0xBC,0xBA,0x87,0x55,0xB4,0x20,0x6E,
0xA2,0x9A,0x48,0xC9,0xF7,0xF7,0xA5,0x71,
0x11,0xCB,0x8C,0x0F,0x7A,0x85,0x8F,0x27,
0xDE,0x84,0x2B,0x11,0xB7,0x3C,0x9C,0x0A,
0x4E,0x32,0x78,0xFD,0x6A,0xD0,0x58,0x07,
0x5F,0xFE,0xBD,0x58,0xB7,0x04,0x90,0x09,
0x18,0xAA,0x5A,0xEA,0x07,0x49,0xE1,0x6F,
0xF8,0xFC,0x8F,0xD8,0x8A,0xF7,0xAD,0x1A,
0x40,0x34,0xD8,0x47,0x60,0x82,0xBA,0xA8,
0xDA,0xF6,0x22,0xAE,0xD7,0x2D,0x86,0x52,
0x69,0x40,0x5C,0x76,0xAE,0x8B,0x27,0xB1,
0x92,0x60,0x42,0x9E,0xC2,0x9A,0x63,0x43,
0xD5,0x45,0x27,0x04,
0x5A,0x6C,0xE3,0x92,0x6E,0x01,0xA7,0x99,
0xBD,0xC8,0xAC,0xEE,0x6A,0xC0,0xCE,0x7A,
0x64,0xD3,0x4D,0xC1,0xCF,0x53,0x45,0xC8,
0x90,0xD3,0x74,0x41,0xEB,0x54,0x3C,0x47,
0x7A,0xAB,0xA5,0xC8,0x5D,0xB1,0x91,0x8A,
0x99,0x4D,0xD8,0x9B,0x1E,0x69,0xA9,0xCC,
0x0B,0x93,0x90,0x41,0xE9,0x59,0x77,0x13,
0x63,0x9C,0xE6,0xBC,0xE9,0x3D,0x4E,0x9B,
0x15,0xDE,0x75,0xCE,0x72,0x29,0xBE,0x7A,
0xE4,0xFC,0xC3,0x8E,0x94,0xBA,0x92,0x31,
0xE6,0xF4,0x20,0x8A,0x8D,0xA5,0x1C,0xF2,
0x0D,0x55,0xFB,0x03,0x1A,0x64,0x19,0xEA,
0x39,0xA6,0x19,0x46,0x31,0x9C,0x53,0xE6,
0x24,0x74,0x52,0x82,0x71,0x9E,0x6A,0xC4,
0x32,0x7C,0xD5,0x69,0xA1,0xA5,0x73,0x7F,
0xC3,0xD3,0xED,0xBA,0x42,0x0F,0x71,0x5E,
0xD3,0xA5,0x5F,0xB7,0xD8,0x22,0xF6,0x51,
0x5D,0x38,0x75,0xA9,0x15,0x17,0x42,0xDC,
0x7A,0x8B,0x7A,0xF1,0x53,0x2E,0xA0,0xD8,
0xEB,0x5D,0x6D,0x19,0xA4,0x4A,0xB7,0xAC,
0x57,0xAE,0x69,0xE2,0xEC,0xB0,0x1C,0xD0,
0x99,0x56,0x38,0xC4,0x90,0x91,0xF4,0xF6,
0xA7,0x79,0x87,0x3D,0x8D,0x73,0x1B,0x48,
0x43,0x21,0x03,0xA5,0x31,0xA5,0x38,0xED,
0x8A,0x4D,0xE8,0x43,0x44,0x4F,0x2E,0x4E,
0x78,0xFC,0xEA,0xAD,0xEE,0xC9,0xA3,0x68,
0xE4,0x50,0xCA,0xE3,0x04,0x54,0xC9,0xE8,
0x09,0x1C,0x8E,0xB9,0xE1,0x9C,0x96,0x7B,
0x0B,0x96,0x8F,0xBE,0xC7,0xE4,0x57,0x2D,
0xAA,0xE9,0x5A,0xDD,0xB1,0x39,0xB7,0x59,
0x80,0xEE,0x8D,0x5C,0x2D,0xF7,0x35,0xB3,
0xB1,0x8B,0x7B,0x71,0x79,0x6E,0x0F,0x9D,
0x61,0x72,0xB8,0xEB,0x85,0xCF,0xF2,0xAC,
0xF9,0x35,0xD8,0x50,0x9D,0xEB,0x2A,0x11,
0xEA,0xA6,0xAA,0xDA,0x12,0xDF,0x42,0x09,
0x7C,0x45,0x6B,0xDA,0x52,0x0F,0xBD,0x37,
0xFE,0x12,0x1B,0x53,0xD6,0x71,0x83,0x4D,
0x27,0x61,0x0E,0x5D,0x76,0xD0,0x91,0xFB,
0xE1,0x52,0xC7,0xAB,0xDB,0x3A,0xE5,0x64,
0x27,0x3E,0xD4,0xED,0xDC,0x45,0x8B,0x7B,
0xCF,0x30,0xFE,0xEE,0x19,0xA4,0xFF,0x00,
0x75,0x09,0xAD,0x8D,0x36,0xD3,0x57,0xBA,
0x60,0x2D,0xF4,0xBB,0x93,0xEE,0xE3,0x68,
0xFD,0x6A,0x92,0xB6,0xE3,0x5E,0x47,0x59,
0xE1,0x9F,0x0A,0xEA,0xEF,0x32,0x49,0x7D,
0x2A,0x5B,0xC6,0x0E,0x4A,0x21,0xC9,0xAF,
0x4A,0xB1,0x1E,0x55,
0xBA,0x44,0x0E,0x42,0x00,0x2B,0xA6,0x8C,
0x92,0x76,0x42,0x9A,0x2E,0xC2,0xDD,0x39,
0xAB,0x11,0xB7,0xAE,0x6B,0xA1,0x49,0xD8,
0x84,0x89,0xA3,0x7F,0x6C,0xD4,0x8A,0xE4,
0x60,0x0E,0x94,0xFC,
0x86,0x91,0x96,0xB6,0x64,0x8C,0x67,0x1F,
0x85,0x3D,0x74,0xE3,0xD8,0xD6,0x29,0x75,
0x35,0x6C,0x53,0xA5,0xB9,0x34,0xD7,0xD2,
0x1C,0xFE,0x1E,0xD4,0x58,0x96,0xC6,0x3E,
0x89,0x23,0x76,0xA8,0xDF,0x41,0x97,0x3C,
0x0A,0x89,0x2D,0x05,0x7B,0x10,0x4B,0xE1,
0xC9,0x8F,0xF0,0x93,0x9A,0xA9,0x3F,0x85,
0xE6,0x63,0xCA,0xB5,0x72,0x4A,0x9B,0xB9,
0xA2,0x92,0xB1,0x52,0x7F,0x07,0x97,0x07,
0x74,0x4C,0x7F,0x0A,0xCF,0xBB,0xF0,0x05,
0xBC,0xB9,0xDF,0x68,0x0F,0xD5,0x6A,0x7D,
0x9B,0xBE,0xC3,0xBA,0x65,0x0B,0x9F,0x86,
0x3A,0x74,0x87,0x2D,0x60,0x9F,0xF7,0xC5,
0x56,0x3F,0x0B,0x34,0xBD,0xDF,0xF2,0x0F,
0x4F,0xFB,0xE6,0x9A,0x4D,0x03,0x48,0x72,
0x7C,0x34,0xD3,0xE3,0x39,0x5B,0x18,0xF2,
0x3F,0xD8,0xAB,0x76,0xFE,0x07,0x82,0x0C,
0x79,0x76,0x71,0x0F,0xF8,0x00,0xA6,0xD4,
0x81,0x58,0xBD,0x6F,0xE1,0xE6,0x88,0xE1,
0x20,0x55,0x1E,0xCB,0x8A,0xBF,0x6F,0xA6,
0xCE,0x83,0x94,0xC0,0x3E,0xD4,0x72,0xF7,
0x1A,0x65,0xEB,0x6B,0x49,0x43,0x0C,0xA7,
0xE9,0x56,0xE3,0xB7,0x7C,0x7D,0xD3,0xC7,
0x15,0xD1,0x45,0x11,0x32,0x68,0xA3,0x90,
0x11,0x9C,0xE0,0xD5,
0x84,0x57,0xC7,0xDD,0xAE,0x84,0x47,0xA9,
0x2A,0x06,0xE9,0x83,0x4F,0x19,0xF4,0x35,
0x61,0x6E,0xC3,0x62,0xDD,0xDB,0x19,0xAB,
0x30,0x96,0xC7,0x2A,0x0D,0x67,0x72,0x99,
0x61,0x07,0xFB,0x34,0xE5,0x07,0x3F,0x74,
0xD3,0xB5,0xD1,0x2C,0x92,0x31,0x9C,0x70,
0x78,0xA9,0x15,0x7B,0x90,0x71,0x52,0xFC,
0xC4,0xF7,0x14,0x28,0xEE,0x0D,0x2B,0x2A,
0x01,0xE9,0x59,0x35,0xA8,0xC3,0x62,0xFA,
0x0C,0x7A,0xE2,0x97,0xCB,0x4C,0x72,0x01,
0xFC,0x28,0xB2,0x01,0x1E,0x38,0x48,0x1C,
0x0C,0xFD,0x29,0x0C,0x30,0xED,0xFB,0xA3,
0x1F,0x4A,0x2C,0x80,0x69,0xB7,0x80,0x9F,
0xBA,0xB9,0xFA,0x52,0x8B,0x3B,0x7D,0xB9,
0xDA,0xBF,0x95,0x0D,0x21,0x8B,0xF6,0x28,
0x0F,0x1B,0x16,0x83,0x61,0x6F,0x9E,0x23,
0x14,0x38,0xAE,0x81,0x76,0x02,0xC2,0x0C,
0xFF,0x00,0xAB,0x02,0x94,0xE9,0xF6,0xFF,
0x00,0xDD,0xC5,0x5C,0x15,0x84,0xD8,0xD3,
0xA7,0xC1,0x9F,0xBB,0x48,0x74,0xF8,0x73,
0xC6,0x47,0xE3,0x5A,0x8A,0xE0,0x6C,0x23,
0x03,0xA9,0xE2,0x98,0xD6,0x68,0x07,0x04,
0x53,0xB6,0x83,0x4C,0xFF,0xD9
};

#endif

const  uint8_t *tImagesList[] = {image1, image2};
uint16_t tImagesSizes[] = {IMAGE1_SIZE, IMAGE2_SIZE};

/* USER CODE END PFP */

/* USER CODE BEGIN 0 */

#define IMG_NBR                   2U
#define USE_USB_HS 1

 int8_t VIDEO_Itf_Data(uint8_t **pbuf, uint16_t *psize, uint16_t *pcktidx)
{
  /*
    Implementation of this function is mandatory to provide the video data to the USB video class
    This function shall parse the MJPEG images and provide each time the buffer packet relative to
    current packet index and its size.
    If the packet is the first packet in the current MJPEG image, then packet size shall be zero and
    the pbuf is ignored and pcktidx shall be zero.
    Below is typical implementation of this function based on a binary image template.

    Binary image template shall provide:
     - tImagesList: table containing pointers to all images
     - tImagesSizes: table containing sizes of each image respectively
     - img_count: global image counter variable
     - IMG_NBR: Total image number

     To generate such file, it is possible to use tools converting video to MJPEG then to JPEG images.

  */

#ifdef USBD_UVC_FORMAT_UNCOMPRESSED
	  const uint8_t *(*ImagePtr) = tImagesList;
	  uint32_t packet_count = (tImagesSizes[img_count]) / ((UVC_PACKET_SIZE - (UVC_HEADER_PACKET_CNT * 2U)));
	  uint32_t packet_remainder = (tImagesSizes[img_count]) % ((UVC_PACKET_SIZE - (UVC_HEADER_PACKET_CNT * 2U)));
	  static uint8_t packet_index = 0U;

	  /* Check if end of current image has been reached */
	  if (packet_index < packet_count)
	  {
	    /* Set the current packet size */
	    *psize = (uint16_t)UVC_PACKET_SIZE;

	    /* Get the pointer to the next packet to be transmitted */
	    *pbuf = (uint8_t *)(*(ImagePtr + img_count) + \
	                        (packet_index * ((uint16_t)(UVC_PACKET_SIZE - (UVC_HEADER_PACKET_CNT * 2U)))));
	  }
	  else if ((packet_index == packet_count))
	  {
	    if (packet_remainder != 0U)
	    {
	      /* Get the pointer to the next packet to be transmitted */
	      *pbuf = (uint8_t *)(*(ImagePtr + img_count) + \
	                          (packet_index * ((uint16_t)(UVC_PACKET_SIZE - (UVC_HEADER_PACKET_CNT * 2U)))));

	      /* Set the current packet size */
	      *psize = (uint16_t)(packet_remainder + (UVC_HEADER_PACKET_CNT * 2U));
	    }
	    else
	    {
	      packet_index++;

	      /* New image to be started, send only the packet header */
	      *psize = 2;
	    }
	  }
	  else
	  {
	    /* New image to be started, send only the packet header */
	    *psize = 2;
	  }

	  /* Update the packet index */
	  *pcktidx = packet_index;

	  /* Increment the packet count and check if it reached the end of current image buffer */
	  if (packet_index++ >= (packet_count + 1U))
	  {
	    /* Reset the packet count to zero */
	    packet_index = 0U;

	    /* Move to the next image in the images table */

	    img_count++;

	    /* Check if images count has been reached, then reset to zero (go back to first image in circular loop) */
	    if (img_count == IMG_NBR)
	    {
	      img_count = 0U;
	    }
	  }

#else
  const uint8_t *(*ImagePtr) = tImagesList;
  uint32_t packet_count = (tImagesSizes[img_count]) / ((UVC_PACKET_SIZE - (UVC_HEADER_PACKET_CNT * 2U)));
  uint32_t packet_remainder = (tImagesSizes[img_count]) % ((UVC_PACKET_SIZE - (UVC_HEADER_PACKET_CNT * 2U)));
  static uint8_t packet_index = 0U;

  /* Check if end of current image has been reached */
  if (packet_index < packet_count)
  {
    /* Set the current packet size */
    *psize = (uint16_t)UVC_PACKET_SIZE;

    /* Get the pointer to the next packet to be transmitted */
    *pbuf = (uint8_t *)(*(ImagePtr + img_count) + \
                        (packet_index * ((uint16_t)(UVC_PACKET_SIZE - (UVC_HEADER_PACKET_CNT * 2U)))));
  }
  else if ((packet_index == packet_count))
  {
    if (packet_remainder != 0U)
    {
      /* Get the pointer to the next packet to be transmitted */
      *pbuf = (uint8_t *)(*(ImagePtr + img_count) + \
                          (packet_index * ((uint16_t)(UVC_PACKET_SIZE - (UVC_HEADER_PACKET_CNT * 2U)))));

      /* Set the current packet size */
      *psize = (uint16_t)(packet_remainder + (UVC_HEADER_PACKET_CNT * 2U));
    }
    else
    {
      packet_index++;

      /* New image to be started, send only the packet header */
      *psize = 2;
    }
  }
  else
  {
    /* New image to be started, send only the packet header */
    *psize = 2;
  }

  /* Update the packet index */
  *pcktidx = packet_index;

  /* Increment the packet count and check if it reached the end of current image buffer */
  if (packet_index++ >= (packet_count + 1U))
  {
    /* Reset the packet count to zero */
    packet_index = 0U;

    /* Move to the next image in the images table */

    img_count++;

    /* Check if images count has been reached, then reset to zero (go back to first image in circular loop) */
    if (img_count == IMG_NBR)
    {
      img_count = 0U;
    }
  }

#endif
    return (0);
}

 typedef enum
 {
  UVC_STS_INIT = 0,
  UVC_STS_WAIT_CAMSTART = 1,
  UVC_STS_WAIT_CAMSTOPP = 2,
 }eUVC_Status;
 eUVC_Status UVC_Status = UVC_STS_INIT;
 extern uint8_t USBD_VIDEO_Init(USBD_HandleTypeDef *pdev, uint8_t cfgidx);
 extern uint8_t USBD_VIDEO_DeInit(USBD_HandleTypeDef *pdev, uint8_t cfgidx);
 extern uint8_t USBD_VIDEO_SOF(USBD_HandleTypeDef *pdev);

/* USER CODE END 0 */

int main(void)
{

  /* MCU Configuration--------------------------------------------------------*/

  /* Reset of all peripherals, Initializes the Flash interface and the Systick. */
  HAL_Init();

  /* Configure the system clock */
  SystemClock_Config();

  /* Initialize all configured peripherals */
  MX_GPIO_Init();
  MX_USB_OTG_HS_PCD_Init();
  /* USER CODE BEGIN 2 */
  MX_USB_DEVICE_Init();//user modify

  /* USER CODE END 2 */

  /* Infinite loop */
  /* USER CODE BEGIN WHILE */
  while (1)
  {
		switch (UVC_Status)
		{
			case UVC_STS_INIT:
				//MX_USB_DEVICE_Init();
				UVC_Status = UVC_STS_WAIT_CAMSTART;
				break;
			case UVC_STS_WAIT_CAMSTART:
				if (USBD_VIDEO_Instance.uvc_state == UVC_PLAY_STATUS_READY)
				{
					USBD_VIDEO_SOF(&hUsbDevice);
					UVC_Status = UVC_STS_WAIT_CAMSTOPP;
				}
				break;
			case UVC_STS_WAIT_CAMSTOPP:
				if (USBD_VIDEO_Instance.uvc_state == UVC_PLAY_STATUS_STOP)
				{
					USBD_VIDEO_DeInit(&hUsbDevice,0);
					USBD_VIDEO_Init(&hUsbDevice,0);
					UVC_Status = UVC_STS_INIT;
				}
				break;

		}//sw
    /* USER CODE END WHILE */

  }
}

void SystemClock_Config(void)
{
  RCC_OscInitTypeDef RCC_OscInitStruct = {0};
  RCC_ClkInitTypeDef RCC_ClkInitStruct = {0};

  /** Configure the main internal regulator output voltage
  */
  __HAL_RCC_PWR_CLK_ENABLE();
  __HAL_PWR_VOLTAGESCALING_CONFIG(PWR_REGULATOR_VOLTAGE_SCALE1);

  /** Initializes the RCC Oscillators according to the specified parameters
  * in the RCC_OscInitTypeDef structure.
  */
  RCC_OscInitStruct.OscillatorType = RCC_OSCILLATORTYPE_HSI|RCC_OSCILLATORTYPE_HSE;
  RCC_OscInitStruct.HSEState = RCC_HSE_ON;
  RCC_OscInitStruct.HSIState = RCC_HSI_ON;
  RCC_OscInitStruct.HSICalibrationValue = RCC_HSICALIBRATION_DEFAULT;
  RCC_OscInitStruct.PLL.PLLState = RCC_PLL_ON;
  RCC_OscInitStruct.PLL.PLLSource = RCC_PLLSOURCE_HSI;
  RCC_OscInitStruct.PLL.PLLM = 8;
  RCC_OscInitStruct.PLL.PLLN = 168;
  RCC_OscInitStruct.PLL.PLLP = RCC_PLLP_DIV2;
  RCC_OscInitStruct.PLL.PLLQ = 4;
  if (HAL_RCC_OscConfig(&RCC_OscInitStruct) != HAL_OK)
  {
    Error_Handler();
  }

  /** Initializes the CPU, AHB and APB buses clocks
  */
  RCC_ClkInitStruct.ClockType = RCC_CLOCKTYPE_HCLK|RCC_CLOCKTYPE_SYSCLK
                              |RCC_CLOCKTYPE_PCLK1|RCC_CLOCKTYPE_PCLK2;
  RCC_ClkInitStruct.SYSCLKSource = RCC_SYSCLKSOURCE_PLLCLK;
  RCC_ClkInitStruct.AHBCLKDivider = RCC_SYSCLK_DIV1;
  RCC_ClkInitStruct.APB1CLKDivider = RCC_HCLK_DIV4;
  RCC_ClkInitStruct.APB2CLKDivider = RCC_HCLK_DIV2;

  if (HAL_RCC_ClockConfig(&RCC_ClkInitStruct, FLASH_LATENCY_5) != HAL_OK)
  {
    Error_Handler();
  }
  HAL_RCC_MCOConfig(RCC_MCO1, RCC_MCO1SOURCE_HSE, RCC_MCODIV_1);
}

void Error_Handler(void)
{
  __disable_irq();
  while (1)
  {
  }
}
